VERSION ""

NS_ :

BS_:

BU_: VCU BMS ECUMASTER_GPS_IMU AMK_RL AMK_RR AMK_FL AML_FR BOSCH_IMU

BO_ 256 VCU_STATUS: 4 VCU
 SG_ VEHICLE_STATE : 0|2@1+ (1,0) [0|3] "Enum" Vector__XXX
 SG_ TORQUE_PLAUSIBLE : 2|1@1+ (1,0) [0|1] "Bool" Vector__XXX
 SG_ PEDALS_PLAUSIBLE : 3|1@1+ (1,0) [0|1] "Bool" Vector__XXX
 SG_ TORQUE_DERATING : 4|1@1+ (1,0) [0|1] "Bool" Vector__XXX
 SG_ VCU_EEPROM_STATE : 5|2@1+ (1,0) [0|1] "Enum" Vector__XXX
 SG_ CAN_PLAUSIBLE : 7|1@1+ (1,0) [0|1] "Bool" Vector__XXX
 SG_ APPS_1_PLAUSIBLE : 8|1@1+ (1,0) [0|1] "Bool" Vector__XXX
 SG_ APPS_1_CONFIG_PLAUSIBLE : 9|1@1+ (1,0) [0|1] "Bool" Vector__XXX
 SG_ APPS_2_PLAUSIBLE : 10|1@1+ (1,0) [0|1] "Bool" Vector__XXX
 SG_ APPS_2_CONFIG_PLAUSIBLE : 11|1@1+ (1,0) [0|1] "Bool" Vector__XXX
 SG_ BSE_F_PLAUSIBLE : 12|1@1+ (1,0) [0|1] "Bool" Vector__XXX
 SG_ BSE_F_CONFIG_PLAUSIBLE : 13|1@1+ (1,0) [0|1] "Bool" Vector__XXX
 SG_ BSE_R_PLAUSIBLE : 14|1@1+ (1,0) [0|1] "Bool" Vector__XXX
 SG_ BSE_R_CONFIG_PLAUSIBLE : 15|1@1+ (1,0) [0|1] "Bool" Vector__XXX
 SG_ AMK_RL_VALID : 16|1@1+ (1,0) [0|1] "Bool" Vector__XXX
 SG_ AMK_RR_VALID : 17|1@1+ (1,0) [0|1] "Bool" Vector__XXX
 SG_ AMK_FL_VALID : 18|1@1+ (1,0) [0|1] "Bool" Vector__XXX
 SG_ AMK_FR_VALID : 19|1@1+ (1,0) [0|1] "Bool" Vector__XXX
 SG_ ECUMASTER_STATUS : 20|2@1+ (1,0) [0|3] "Enum" Vector__XXX
 SG_ GLV_BATTERY_VOLTAGE : 24|8@1+ (0.070588235294,0) [0|18] "V" Vector__XXX
 SG_ SAS_STATE : 22|2@1+ (1,0) [0|3] "Enum" Vector__XXX

BO_ 1831 BMS_STATUS: 6 BMS
 SG_ BMS_UNDERVOLTAGE_FAULT : 0|1@1+ (1,0) [0|1] "Bool" Vector__XXX
 SG_ BMS_OVERVOLTAGE_FAULT : 1|1@1+ (1,0) [0|1] "Bool" Vector__XXX
 SG_ BMS_UNDERTEMPERATURE_FAULT : 2|1@1+ (1,0) [0|1] "Bool" Vector__XXX
 SG_ BMS_OVERTEMPERATURE_FAULT : 3|1@1+ (1,0) [0|1] "Bool" Vector__XXX
 SG_ BMS_SENSE_LINE_FAULT : 4|1@1+ (1,0) [0|1] "Bool" Vector__XXX
 SG_ BMS_ISOSPI_FAULT : 5|1@1+ (1,0) [0|1] "Bool" Vector__XXX
 SG_ BMS_SELF_TEST_FAULT : 6|1@1+ (1,0) [0|1] "Bool" Vector__XXX
 SG_ BMS_LTC_0_ISOSPI_FAULT : 16|1@1+ (1,0) [0|1] "Bool" Vector__XXX
 SG_ BMS_LTC_1_ISOSPI_FAULT : 17|1@1+ (1,0) [0|1] "Bool" Vector__XXX
 SG_ BMS_LTC_2_ISOSPI_FAULT : 18|1@1+ (1,0) [0|1] "Bool" Vector__XXX
 SG_ BMS_LTC_3_ISOSPI_FAULT : 19|1@1+ (1,0) [0|1] "Bool" Vector__XXX
 SG_ BMS_LTC_4_ISOSPI_FAULT : 20|1@1+ (1,0) [0|1] "Bool" Vector__XXX
 SG_ BMS_LTC_5_ISOSPI_FAULT : 21|1@1+ (1,0) [0|1] "Bool" Vector__XXX
 SG_ BMS_LTC_6_ISOSPI_FAULT : 22|1@1+ (1,0) [0|1] "Bool" Vector__XXX
 SG_ BMS_LTC_7_ISOSPI_FAULT : 23|1@1+ (1,0) [0|1] "Bool" Vector__XXX
 SG_ BMS_LTC_8_ISOSPI_FAULT : 24|1@1+ (1,0) [0|1] "Bool" Vector__XXX
 SG_ BMS_LTC_9_ISOSPI_FAULT : 25|1@1+ (1,0) [0|1] "Bool" Vector__XXX
 SG_ BMS_LTC_10_ISOSPI_FAULT : 26|1@1+ (1,0) [0|1] "Bool" Vector__XXX
 SG_ BMS_LTC_11_ISOSPI_FAULT : 27|1@1+ (1,0) [0|1] "Bool" Vector__XXX
 SG_ BMS_LTC_0_SELF_TEST_FAULT : 32|1@1+ (1,0) [0|1] "Bool" Vector__XXX
 SG_ BMS_LTC_1_SELF_TEST_FAULT : 33|1@1+ (1,0) [0|1] "Bool" Vector__XXX
 SG_ BMS_LTC_2_SELF_TEST_FAULT : 34|1@1+ (1,0) [0|1] "Bool" Vector__XXX
 SG_ BMS_LTC_3_SELF_TEST_FAULT : 35|1@1+ (1,0) [0|1] "Bool" Vector__XXX
 SG_ BMS_LTC_4_SELF_TEST_FAULT : 36|1@1+ (1,0) [0|1] "Bool" Vector__XXX
 SG_ BMS_LTC_5_SELF_TEST_FAULT : 37|1@1+ (1,0) [0|1] "Bool" Vector__XXX
 SG_ BMS_LTC_6_SELF_TEST_FAULT : 38|1@1+ (1,0) [0|1] "Bool" Vector__XXX
 SG_ BMS_LTC_7_SELF_TEST_FAULT : 39|1@1+ (1,0) [0|1] "Bool" Vector__XXX
 SG_ BMS_LTC_8_SELF_TEST_FAULT : 40|1@1+ (1,0) [0|1] "Bool" Vector__XXX
 SG_ BMS_LTC_9_SELF_TEST_FAULT : 41|1@1+ (1,0) [0|1] "Bool" Vector__XXX
 SG_ BMS_LTC_10_SELF_TEST_FAULT : 42|1@1+ (1,0) [0|1] "Bool" Vector__XXX
 SG_ BMS_LTC_11_SELF_TEST_FAULT : 43|1@1+ (1,0) [0|1] "Bool" Vector__XXX
 SG_ BMS_CHARGING : 7|1@1+ (1,0) [0|1] "Bool" Vector__XXX
 SG_ BMS_BALANCING : 8|1@1+ (1,0) [0|1] "Bool" Vector__XXX
 SG_ SHUTDOWN_CLOSED : 9|1@1+ (1,0) [0|1] "Bool" Vector__XXX
 SG_ PRECHARGE_COMPLETE : 10|1@1+ (1,0) [0|1] "Bool" Vector__XXX
 SG_ SHUTDOWN_LOOP_BLIP : 11|1@1+ (1,0) [0|1] "Bool" Vector__XXX
 SG_ BMS_RELAY_STATUS : 12|1@1+ (1,0) [0|1] "Bool" Vector__XXX
 SG_ IMD_RELAY_STATUS : 13|1@1+ (1,0) [0|1] "Bool" Vector__XXX

BO_ 1536 VCU_SENSOR_INPUT: 8 VCU
 SG_ APPS_1_PERCENT : 0|12@1+ (0.02442002442002442,0) [0|100] "%" Vector__XXX
 SG_ APPS_2_PERCENT : 12|12@1+ (0.02442002442002442,0) [0|100] "%" Vector__XXX
 SG_ BSE_FRONT_PERCENT : 24|12@1+ (0.02442002442002442,0) [0|100] "%" Vector__XXX
 SG_ BSE_REAR_PERCENT : 36|12@1+ (0.02442002442002442,0) [0|100] "%" Vector__XXX
 SG_ STEERING_ANGLE : 48|16@1- (0.005493247882810711,0) [-180|180] "Deg" Vector__XXX

BO_ 1832 BMS_POWER_CONSUMPTION: 4 BMS
 SG_ PACK_VOLTAGE : 0|16@1+ (0.0125,0) [0|819.2] "V" Vector__XXX
 SG_ PACK_CURRENT : 16|16@1- (0.019073486328125,0) [-625|625] "A" Vector__XXX

BO_ 512 AMK_RL_MOTOR_REQUEST: 8 VCU
 SG_ RL_INVERTER_ENABLE : 8|1@1+ (1,0) [0|1] "" Vector__XXX
 SG_ RL_DC_ENABLE : 9|1@1+ (1,0) [0|1] "" Vector__XXX
 SG_ RL_DRIVER_ENABLE : 10|1@1+ (1,0) [0|1] "" Vector__XXX
 SG_ RL_ERROR_RESET : 11|1@1+ (1,0) [0|1] "" Vector__XXX
 SG_ RL_TORQUE_SETPOINT : 16|16@1- (0.0098,0) [-21|21] "Nm" Vector__XXX
 SG_ RL_POSITIVE_TORQUE_LIMIT : 32|16@1- (0.0098,0) [0|21] "Nm" Vector__XXX
 SG_ RL_NEGATIVE_TORQUE_LIMIT : 48|16@1- (0.0098,0) [0|21] "Nm" Vector__XXX

BO_ 513 AMK_RR_MOTOR_REQUEST: 8 VCU
 SG_ RR_INVERTER_ENABLE : 8|1@1+ (1,0) [0|1] "" Vector__XXX
 SG_ RR_DC_ENABLE : 9|1@1+ (1,0) [0|1] "" Vector__XXX
 SG_ RR_DRIVER_ENABLE : 10|1@1+ (1,0) [0|1] "" Vector__XXX
 SG_ RR_ERROR_RESET : 11|1@1+ (1,0) [0|1] "" Vector__XXX
 SG_ RR_TORQUE_SETPOINT : 16|16@1- (0.0098,0) [-21|21] "Nm" Vector__XXX
 SG_ RR_POSITIVE_TORQUE_LIMIT : 32|16@1- (0.0098,0) [0|21] "Nm" Vector__XXX
 SG_ RR_NEGATIVE_TORQUE_LIMIT : 48|16@1- (0.0098,0) [0|21] "Nm" Vector__XXX

BO_ 514 AMK_FL_MOTOR_REQUEST: 8 VCU
 SG_ FL_INVERTER_ENABLE : 8|1@1+ (1,0) [0|1] "" Vector__XXX
 SG_ FL_DC_ENABLE : 9|1@1+ (1,0) [0|1] "" Vector__XXX
 SG_ FL_DRIVER_ENABLE : 10|1@1+ (1,0) [0|1] "" Vector__XXX
 SG_ FL_ERROR_RESET : 11|1@1+ (1,0) [0|1] "" Vector__XXX
 SG_ FL_TORQUE_SETPOINT : 16|16@1- (0.0098,0) [-21|21] "Nm" Vector__XXX
 SG_ FL_POSITIVE_TORQUE_LIMIT : 32|16@1- (0.0098,0) [0|21] "Nm" Vector__XXX
 SG_ FL_NEGATIVE_TORQUE_LIMIT : 48|16@1- (0.0098,0) [0|21] "Nm" Vector__XXX

BO_ 515 AMK_FR_MOTOR_REQUEST: 8 VCU
 SG_ FR_INVERTER_ENABLE : 8|1@1+ (1,0) [0|1] "" Vector__XXX
 SG_ FR_DC_ENABLE : 9|1@1+ (1,0) [0|1] "" Vector__XXX
 SG_ FR_DRIVER_ENABLE : 10|1@1+ (1,0) [0|1] "" Vector__XXX
 SG_ FR_ERROR_RESET : 11|1@1+ (1,0) [0|1] "" Vector__XXX
 SG_ FR_TORQUE_SETPOINT : 16|16@1- (0.0098,0) [-21|21] "Nm" Vector__XXX
 SG_ FR_POSITIVE_TORQUE_LIMIT : 32|16@1- (0.0098,0) [0|21] "Nm" Vector__XXX
 SG_ FR_NEGATIVE_TORQUE_LIMIT : 48|16@1- (0.0098,0) [0|21] "Nm" Vector__XXX

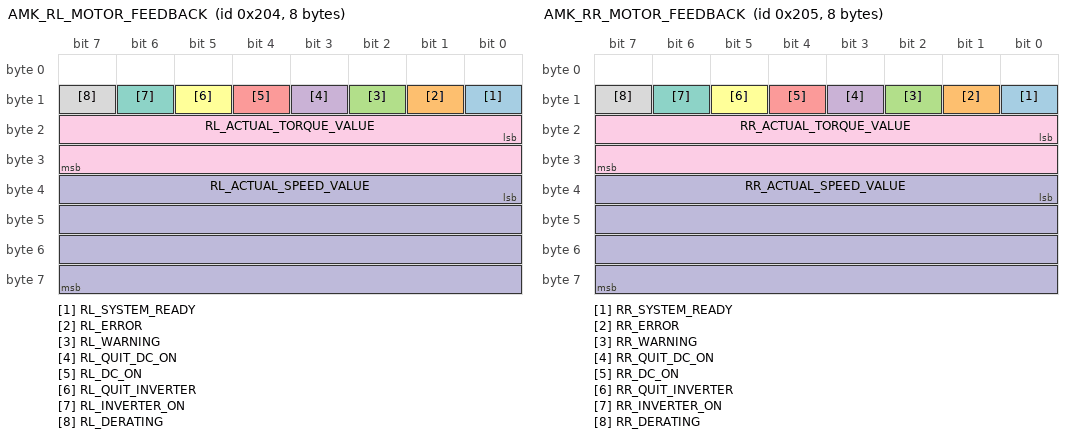
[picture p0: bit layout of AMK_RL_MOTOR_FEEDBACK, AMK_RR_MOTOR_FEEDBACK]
BO_ 516 AMK_RL_MOTOR_FEEDBACK: 8 AMK_RL
 SG_ RL_SYSTEM_READY : 8|1@1+ (1,0) [0|1] "Bool" Vector__XXX
 SG_ RL_ERROR : 9|1@1+ (1,0) [0|1] "Bool" Vector__XXX
 SG_ RL_WARNING : 10|1@1+ (1,0) [0|1] "Bool" Vector__XXX
 SG_ RL_QUIT_DC_ON : 11|1@1+ (1,0) [0|1] "Bool" Vector__XXX
 SG_ RL_DC_ON : 12|1@1+ (1,0) [0|1] "Bool" Vector__XXX
 SG_ RL_QUIT_INVERTER : 13|1@1+ (1,0) [0|1] "Bool" Vector__XXX
 SG_ RL_INVERTER_ON : 14|1@1+ (1,0) [0|1] "Bool" Vector__XXX
 SG_ RL_DERATING : 15|1@1+ (1,0) [0|1] "Bool" Vector__XXX
 SG_ RL_ACTUAL_TORQUE_VALUE : 16|16@1- (0.0098,0) [0|0] "Nm" Vector__XXX
 SG_ RL_ACTUAL_SPEED_VALUE : 32|32@1- (0.0001,0) [0|0] "RPM" Vector__XXX

BO_ 517 AMK_RR_MOTOR_FEEDBACK: 8 AMK_RR
 SG_ RR_SYSTEM_READY : 8|1@1+ (1,0) [0|1] "Bool" Vector__XXX
 SG_ RR_ERROR : 9|1@1+ (1,0) [0|1] "Bool" Vector__XXX
 SG_ RR_WARNING : 10|1@1+ (1,0) [0|1] "Bool" Vector__XXX
 SG_ RR_QUIT_DC_ON : 11|1@1+ (1,0) [0|1] "Bool" Vector__XXX
 SG_ RR_DC_ON : 12|1@1+ (1,0) [0|1] "Bool" Vector__XXX
 SG_ RR_QUIT_INVERTER : 13|1@1+ (1,0) [0|1] "Bool" Vector__XXX
 SG_ RR_INVERTER_ON : 14|1@1+ (1,0) [0|1] "Bool" Vector__XXX
 SG_ RR_DERATING : 15|1@1+ (1,0) [0|1] "Bool" Vector__XXX
 SG_ RR_ACTUAL_TORQUE_VALUE : 16|16@1- (0.0098,0) [0|0] "Nm" Vector__XXX
 SG_ RR_ACTUAL_SPEED_VALUE : 32|32@1- (0.0001,0) [0|0] "RPM" Vector__XXX

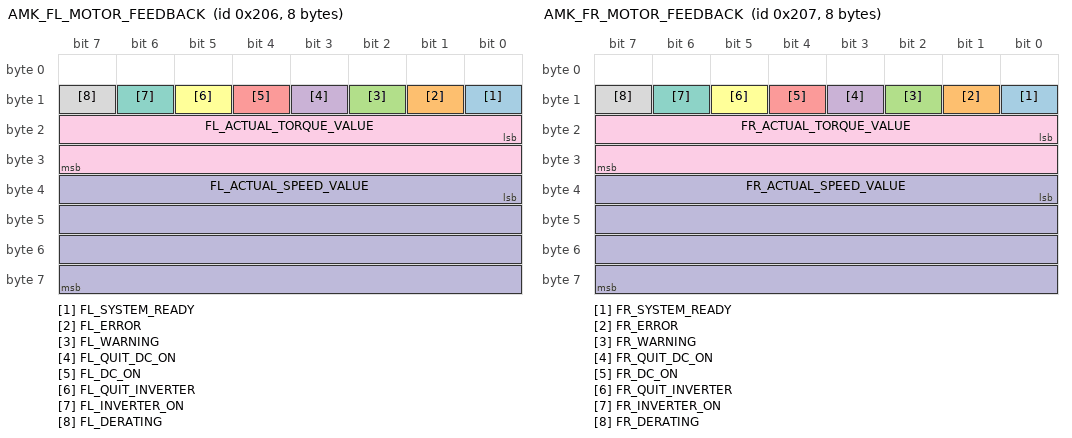
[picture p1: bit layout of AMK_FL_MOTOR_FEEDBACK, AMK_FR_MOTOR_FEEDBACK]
BO_ 518 AMK_FL_MOTOR_FEEDBACK: 8 AMK_FL
 SG_ FL_SYSTEM_READY : 8|1@1+ (1,0) [0|1] "Bool" Vector__XXX
 SG_ FL_ERROR : 9|1@1+ (1,0) [0|1] "Bool" Vector__XXX
 SG_ FL_WARNING : 10|1@1+ (1,0) [0|1] "Bool" Vector__XXX
 SG_ FL_QUIT_DC_ON : 11|1@1+ (1,0) [0|1] "Bool" Vector__XXX
 SG_ FL_DC_ON : 12|1@1+ (1,0) [0|1] "Bool" Vector__XXX
 SG_ FL_QUIT_INVERTER : 13|1@1+ (1,0) [0|1] "Bool" Vector__XXX
 SG_ FL_INVERTER_ON : 14|1@1+ (1,0) [0|1] "Bool" Vector__XXX
 SG_ FL_DERATING : 15|1@1+ (1,0) [0|1] "Bool" Vector__XXX
 SG_ FL_ACTUAL_TORQUE_VALUE : 16|16@1- (0.0098,0) [0|0] "Nm" Vector__XXX
 SG_ FL_ACTUAL_SPEED_VALUE : 32|32@1- (0.0001,0) [0|0] "RPM" Vector__XXX

BO_ 519 AMK_FR_MOTOR_FEEDBACK: 8 AMK_FR
 SG_ FR_SYSTEM_READY : 8|1@1+ (1,0) [0|1] "Bool" Vector__XXX
 SG_ FR_ERROR : 9|1@1+ (1,0) [0|1] "Bool" Vector__XXX
 SG_ FR_WARNING : 10|1@1+ (1,0) [0|1] "Bool" Vector__XXX
 SG_ FR_QUIT_DC_ON : 11|1@1+ (1,0) [0|1] "Bool" Vector__XXX
 SG_ FR_DC_ON : 12|1@1+ (1,0) [0|1] "Bool" Vector__XXX
 SG_ FR_QUIT_INVERTER : 13|1@1+ (1,0) [0|1] "Bool" Vector__XXX
 SG_ FR_INVERTER_ON : 14|1@1+ (1,0) [0|1] "Bool" Vector__XXX
 SG_ FR_DERATING : 15|1@1+ (1,0) [0|1] "Bool" Vector__XXX
 SG_ FR_ACTUAL_TORQUE_VALUE : 16|16@1- (0.0098,0) [0|0] "Nm" Vector__XXX
 SG_ FR_ACTUAL_SPEED_VALUE : 32|32@1- (0.0001,0) [0|0] "RPM" Vector__XXX

BO_ 1284 AMK_RL_ERRORS_1: 8 AMK_RL
 SG_ RL_DIAGNOSTIC_NUMBER : 0|32@1+ (1,0) [0|4294967295] "Word" Vector__XXX
 SG_ RL_ERROR_INFO_1 : 32|32@1+ (1,0) [0|4294967295] "Word" Vector__XXX

BO_ 1285 AMK_RR_ERRORS_1: 8 AMK_RR
 SG_ RR_DIAGNOSTIC_NUMBER : 0|32@1+ (1,0) [0|4294967295] "Word" Vector__XXX
 SG_ RR_ERROR_INFO_1 : 32|32@1+ (1,0) [0|4294967295] "Word" Vector__XXX

BO_ 1286 AMK_FL_ERRORS_1: 8 AMK_FL
 SG_ FL_DIAGNOSTIC_NUMBER : 0|32@1+ (1,0) [0|4294967295] "Word" Vector__XXX
 SG_ FL_ERROR_INFO_1 : 32|32@1+ (1,0) [0|4294967295] "Word" Vector__XXX

BO_ 1287 AMK_FR_ERRORS_1: 8 AMK_FR
 SG_ FR_DIAGNOSTIC_NUMBER : 0|32@1+ (1,0) [0|4294967295] "Word" Vector__XXX
 SG_ FR_ERROR_INFO_1 : 32|32@1+ (1,0) [0|4294967295] "Word" Vector__XXX

BO_ 1288 AMK_RL_ERRORS_2: 8 AMK_RL
 SG_ RL_ERROR_INFO_2 : 0|32@1+ (1,0) [0|4294967295] "Word" Vector__XXX
 SG_ RL_ERROR_INFO_3 : 32|32@1+ (1,0) [0|4294967295] "Word" Vector__XXX

BO_ 1289 AMK_RR_ERRORS_2: 8 AMK_RR
 SG_ RR_ERROR_INFO_2 : 0|32@1+ (1,0) [0|4294967295] "Word" Vector__XXX
 SG_ RR_ERROR_INFO_3 : 32|32@1+ (1,0) [0|4294967295] "Word" Vector__XXX

BO_ 1290 AMK_FL_ERRORS_2: 8 AMK_FL
 SG_ FL_ERROR_INFO_2 : 0|32@1+ (1,0) [0|4294967295] "Word" Vector__XXX
 SG_ FL_ERROR_INFO_3 : 32|32@1+ (1,0) [0|4294967295] "Word" Vector__XXX

BO_ 1291 AMK_FR_ERRORS_2: 8 AMK_FR
 SG_ FR_ERROR_INFO_2 : 0|32@1+ (1,0) [0|4294967295] "Word" Vector__XXX
 SG_ FR_ERROR_INFO_3 : 32|32@1+ (1,0) [0|4294967295] "Word" Vector__XXX

BO_ 520 AMK_RL_POWER_CONSUMPTION: 8 AMK_RL
 SG_ RL_DC_BUS_VOLTAGE : 0|16@1+ (1,0) [0|0] "V" Vector__XXX
 SG_ RL_TORQUE_CURRENT_FEEDBACK : 16|16@1- (1,0) [0|0] "A" Vector__XXX
 SG_ RL_ACTUAL_POWER_VALUE : 32|32@1+ (1,0) [0|0] "W" Vector__XXX

BO_ 521 AMK_RR_POWER_CONSUMPTION: 8 AMK_RR
 SG_ RR_DC_BUS_VOLTAGE : 0|16@1+ (1,0) [0|0] "V" Vector__XXX
 SG_ RR_TORQUE_CURRENT_FEEDBACK : 16|16@1- (1,0) [0|0] "A" Vector__XXX
 SG_ RR_ACTUAL_POWER_VALUE : 32|32@1+ (1,0) [0|0] "W" Vector__XXX

BO_ 522 AMK_FL_POWER_CONSUMPTION: 8 AMK_FL
 SG_ FL_DC_BUS_VOLTAGE : 0|16@1+ (1,0) [0|0] "V" Vector__XXX
 SG_ FL_TORQUE_CURRENT_FEEDBACK : 16|16@1- (1,0) [0|0] "A" Vector__XXX
 SG_ FL_ACTUAL_POWER_VALUE : 32|32@1+ (1,0) [0|0] "W" Vector__XXX

BO_ 523 AMK_FR_POWER_CONSUMPTION: 8 AMK_FR
 SG_ FR_DC_BUS_VOLTAGE : 0|16@1+ (1,0) [0|0] "V" Vector__XXX
 SG_ FR_TORQUE_CURRENT_FEEDBACK : 16|16@1- (1,0) [0|0] "A" Vector__XXX
 SG_ FR_ACTUAL_POWER_VALUE : 32|32@1+ (1,0) [0|0] "W" Vector__XXX

BO_ 1280 AMK_RL_TEMPERATURES: 8 AMK_RL
 SG_ RL_TEMPERATURE_INTERNAL : 0|16@1- (0.1,0) [0|0] "C" Vector__XXX
 SG_ RL_TEMPERATURE_EXTERNAL : 16|16@1- (0.1,0) [0|0] "C" Vector__XXX
 SG_ RL_TEMPERATURE_SENSOR_MOTOR : 32|16@1+ (0.1,0) [0|0] "C" Vector__XXX
 SG_ RL_IGBT_TEMPERATURE : 48|16@1- (0.1,0) [0|0] "C" Vector__XXX

BO_ 1281 AMK_RR_TEMPERATURES: 8 AMK_RR
 SG_ RR_TEMPERATURE_INTERNAL : 0|16@1- (0.1,0) [0|0] "C" Vector__XXX
 SG_ RR_TEMPERATURE_EXTERNAL : 16|16@1- (0.1,0) [0|0] "C" Vector__XXX
 SG_ RR_TEMPERATURE_SENSOR_MOTOR : 32|16@1+ (0.1,0) [0|0] "C" Vector__XXX
 SG_ RR_IGBT_TEMPERATURE : 48|16@1- (0.1,0) [0|0] "C" Vector__XXX

BO_ 1282 AMK_FL_TEMPERATURES: 8 AMK_FL
 SG_ FL_TEMPERATURE_INTERNAL : 0|16@1- (0.1,0) [0|0] "C" Vector__XXX
 SG_ FL_TEMPERATURE_EXTERNAL : 16|16@1- (0.1,0) [0|0] "C" Vector__XXX
 SG_ FL_TEMPERATURE_SENSOR_MOTOR : 32|16@1+ (0.1,0) [0|0] "C" Vector__XXX
 SG_ FL_IGBT_TEMPERATURE : 48|16@1- (0.1,0) [0|0] "C" Vector__XXX

BO_ 1283 AMK_FR_TEMPERATURES: 8 AMK_FR
 SG_ FR_TEMPERATURE_INTERNAL : 0|16@1- (0.1,0) [0|0] "C" Vector__XXX
 SG_ FR_TEMPERATURE_EXTERNAL : 16|16@1- (0.1,0) [0|0] "C" Vector__XXX
 SG_ FR_TEMPERATURE_SENSOR_MOTOR : 32|16@1+ (0.1,0) [0|0] "C" Vector__XXX
 SG_ FR_IGBT_TEMPERATURE : 48|16@1- (0.1,0) [0|0] "C" Vector__XXX

BO_ 1024 ECUMASTER_GPS_POSITION: 8 ECUMASTER_GPS_IMU
 SG_ LATITUDE : 7|32@0- (1e-7,0) [-90|90] "deg" Vector__XXX
 SG_ LONGITUDE : 39|32@0- (1e-7,0) [-180|180] "deg" Vector__XXX

BO_ 1025 ECUMASTER_GPS_VELOCITY: 8 ECUMASTER_GPS_IMU
 SG_ SPEED : 7|16@0- (0.036,0) [-1179|1179] "km/h" Vector__XXX
 SG_ HEIGHT : 23|16@0- (1,0) [-32768|32767] "m" Vector__XXX
 SG_ SATELLITES_NUMBER : 47|8@0+ (1,0) [0|72] "" Vector__XXX
 SG_ GPS_FRAME_INDEX : 51|4@0+ (1,0) [0|16] "" Vector__XXX
 SG_ EMPTY_FRAME_INDEX : 55|4@0+ (1,0) [0|16] "" Vector__XXX
 SG_ GPS_STATUS : 58|3@0+ (1,0) [1|5] "" Vector__XXX

BO_ 1026 ECUMASTER_GPS_HEADING_IMU0: 8 ECUMASTER_GPS_IMU
 SG_ HEADING_MOTION : 7|16@0+ (1,0) [0|360] "deg" Vector__XXX
 SG_ HEADING_VEHICLE : 23|16@0+ (1,0) [0|360] "deg" Vector__XXX
 SG_ ECUMASTER_X_ANGLE_RATE : 39|16@0- (0.01,0) [-250|250] "deg/s" Vector__XXX
 SG_ ECUMASTER_Y_ANGLE_RATE : 55|16@0- (0.01,0) [-250|250] "deg/s" Vector__XXX

BO_ 1027 ECUMASTER_GPS_IMU1: 8 ECUMASTER_GPS_IMU
 SG_ ECUMASTER_Z_ANGLE_RATE : 7|16@0- (0.01,0) [-250|250] "deg/s" Vector__XXX
 SG_ ECUMASTER_X_ACCELERATION : 23|16@0- (0.01,0) [-4|4] "g" Vector__XXX
 SG_ ECUMASTER_Y_ACCELERATION : 39|16@0- (0.01,0) [-4|4] "g" Vector__XXX
 SG_ ECUMASTER_Z_ACCELERATION : 55|16@0- (0.01,0) [-4|4] "g" Vector__XXX

BO_ 1028 ECUMASTER_GPS_UTC: 8 ECUMASTER_GPS_IMU
 SG_ UTC_YEAR : 7|8@0+ (1,2000) [2000|2255] "years" Vector__XXX
 SG_ UTC_MONTH : 15|8@0+ (1,0) [1|12] "months" Vector__XXX
 SG_ UTC_DAY : 23|8@0+ (1,0) [1|31] "days" Vector__XXX
 SG_ UTC_HOUR : 31|8@0+ (1,0) [0|23] "hours" Vector__XXX
 SG_ UTC_MINUTE : 39|8@0+ (1,0) [0|59] "minutes" Vector__XXX
 SG_ UTC_SECOND : 47|8@0+ (1,0) [0|59] "s" Vector__XXX
 SG_ UTC_MILLISECOND : 55|16@0+ (0.0152587890625,0) [0|999.99] "ms" Vector__XXX

BO_ 372 BOSCH_IMU_1: 8 BOSCH_IMU
 SG_ BOSCH_Z_ANGLE_RATE : 0|16@1+ (0.005,-163.84) [-163.84|163.84] "deg/s" Vector__XXX
 SG_ BOSCH_Y_ACCELERATION : 32|16@1+ (0.0001274,-4.1746432) [-4.1746432|4.1746432] "g" Vector__XXX

BO_ 376 BOSCH_IMU_2: 8 BOSCH_IMU
 SG_ BOSCH_X_ANGLE_RATE : 0|16@1+ (0.005,-163.84) [-163.84|163.84] "deg/s" Vector__XXX
 SG_ BOSCH_X_ACCELERATION : 32|16@1+ (0.0001274,-4.1746432) [-4.1746432|4.1746432] "g" Vector__XXX

BO_ 380 BOSCH_IMU_3: 8 BOSCH_IMU
 SG_ BOSCH_Z_ACCELERATION : 32|16@1+ (0.0001274,-4.1746432) [-4.1746432|4.1746432] "g" Vector__XXX

BO_ 384 DATA_LOGGER_STATUS: 4 Vector__XXX
 SG_ MIN_BUS_LOAD : 0|8@1+ (0.6,0) [0|153] "%" Vector__XXX
 SG_ MAX_BUS_LOAD : 8|8@1+ (0.6,0) [0|153] "%" Vector__XXX
 SG_ ERROR_FRAME_COUNT : 16|16@1+ (1,0) [0|65535] "" Vector__XXX

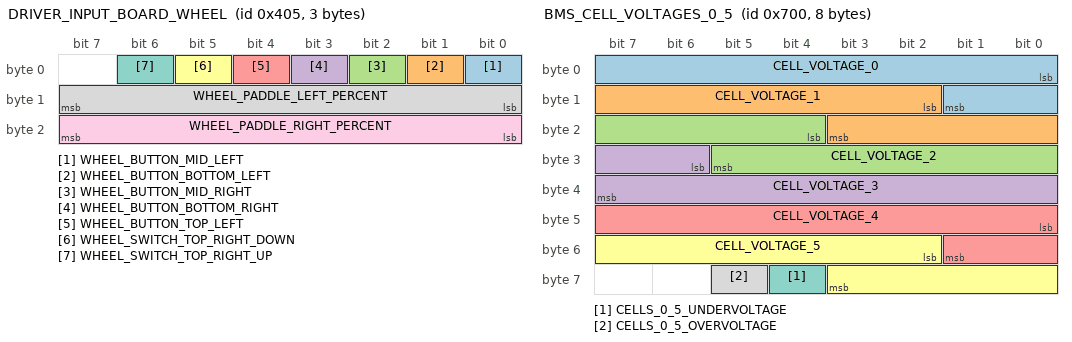
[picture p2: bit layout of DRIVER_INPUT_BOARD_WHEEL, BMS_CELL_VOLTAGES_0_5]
BO_ 1029 DRIVER_INPUT_BOARD_WHEEL: 3 Vector__XXX
 SG_ WHEEL_BUTTON_MID_LEFT : 0|1@1+ (1,0) [0|1] "Bool" Vector__XXX
 SG_ WHEEL_BUTTON_BOTTOM_LEFT : 1|1@1+ (1,0) [0|1] "Bool" Vector__XXX
 SG_ WHEEL_BUTTON_MID_RIGHT : 2|1@1+ (1,0) [0|1] "Bool" Vector__XXX
 SG_ WHEEL_BUTTON_BOTTOM_RIGHT : 3|1@1+ (1,0) [0|1] "Bool" Vector__XXX
 SG_ WHEEL_BUTTON_TOP_LEFT : 4|1@1+ (1,0) [0|1] "Bool" Vector__XXX
 SG_ WHEEL_SWITCH_TOP_RIGHT_DOWN : 5|1@1+ (1,0) [0|1] "Bool" Vector__XXX
 SG_ WHEEL_SWITCH_TOP_RIGHT_UP : 6|1@1+ (1,0) [0|1] "Bool" Vector__XXX
 SG_ WHEEL_PADDLE_LEFT_PERCENT : 8|8@1+ (0.392156862745,0) [0|100] "%" Vector__XXX
 SG_ WHEEL_PADDLE_RIGHT_PERCENT : 16|8@1+ (0.392156862745,0) [0|100] "%" Vector__XXX

BO_ 1952 VEHICLE_CONFIG: 4 VCU
 SG_ DRIVING_TORQUE_LIMIT : 0|8@1+ (0.39215686274509803,0) [0|100] "Nm" Vector__XXX
 SG_ DRIVING_TORQUE_F_R_BIAS : 8|8@1+ (0.00392156862745098,0) [0|1] "Ratio" Vector__XXX
 SG_ DRIVING_TORQUE_L_R_BIAS : 16|8@1+ (0.00392156862745098,0) [0|1] "Ratio" Vector__XXX
 SG_ TORQUE_ALGORITHM_INDEX : 24|8@1+ (1,0) [0|255] "Index" Vector__XXX

BO_ 1956 DRS_STATUS: 2 Vector__XXX
 SG_ THETA_TARGET : 0|10@1+ (0.3515625,-180) [-180|180] "" Vector__XXX
 SG_ WING_STATUS : 10|3@1+ (1,0) [0|7] "" Vector__XXX
 SG_ EEPROM_STATUS : 13|2@1+ (1,0) [0|3] "" Vector__XXX
 SG_ STALLED : 15|1@1+ (1,0) [0|1] "" Vector__XXX

BO_ 1792 BMS_CELL_VOLTAGES_0_5: 8 BMS
 SG_ CELL_VOLTAGE_0 : 0|10@1+ (0.0078125,0) [0|8] "V" Vector__XXX
 SG_ CELL_VOLTAGE_1 : 10|10@1+ (0.0078125,0) [0|8] "V" Vector__XXX
 SG_ CELL_VOLTAGE_2 : 20|10@1+ (0.0078125,0) [0|8] "V" Vector__XXX
 SG_ CELL_VOLTAGE_3 : 30|10@1+ (0.0078125,0) [0|8] "V" Vector__XXX
 SG_ CELL_VOLTAGE_4 : 40|10@1+ (0.0078125,0) [0|8] "V" Vector__XXX
 SG_ CELL_VOLTAGE_5 : 50|10@1+ (0.0078125,0) [0|8] "V" Vector__XXX
 SG_ CELLS_0_5_UNDERVOLTAGE : 60|1@1+ (1,0) [0|1] "Bool" Vector__XXX
 SG_ CELLS_0_5_OVERVOLTAGE : 61|1@1+ (1,0) [0|1] "Bool" Vector__XXX

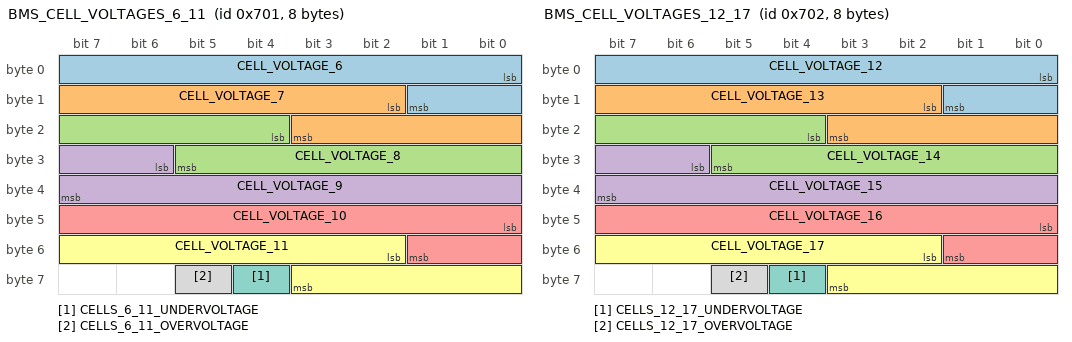
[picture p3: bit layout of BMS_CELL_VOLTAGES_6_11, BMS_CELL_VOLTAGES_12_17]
BO_ 1793 BMS_CELL_VOLTAGES_6_11: 8 BMS
 SG_ CELL_VOLTAGE_6 : 0|10@1+ (0.0078125,0) [0|8] "V" Vector__XXX
 SG_ CELL_VOLTAGE_7 : 10|10@1+ (0.0078125,0) [0|8] "V" Vector__XXX
 SG_ CELL_VOLTAGE_8 : 20|10@1+ (0.0078125,0) [0|8] "V" Vector__XXX
 SG_ CELL_VOLTAGE_9 : 30|10@1+ (0.0078125,0) [0|8] "V" Vector__XXX
 SG_ CELL_VOLTAGE_10 : 40|10@1+ (0.0078125,0) [0|8] "V" Vector__XXX
 SG_ CELL_VOLTAGE_11 : 50|10@1+ (0.0078125,0) [0|8] "V" Vector__XXX
 SG_ CELLS_6_11_UNDERVOLTAGE : 60|1@1+ (1,0) [0|1] "Bool" Vector__XXX
 SG_ CELLS_6_11_OVERVOLTAGE : 61|1@1+ (1,0) [0|1] "Bool" Vector__XXX

BO_ 1794 BMS_CELL_VOLTAGES_12_17: 8 BMS
 SG_ CELL_VOLTAGE_12 : 0|10@1+ (0.0078125,0) [0|8] "V" Vector__XXX
 SG_ CELL_VOLTAGE_13 : 10|10@1+ (0.0078125,0) [0|8] "V" Vector__XXX
 SG_ CELL_VOLTAGE_14 : 20|10@1+ (0.0078125,0) [0|8] "V" Vector__XXX
 SG_ CELL_VOLTAGE_15 : 30|10@1+ (0.0078125,0) [0|8] "V" Vector__XXX
 SG_ CELL_VOLTAGE_16 : 40|10@1+ (0.0078125,0) [0|8] "V" Vector__XXX
 SG_ CELL_VOLTAGE_17 : 50|10@1+ (0.0078125,0) [0|8] "V" Vector__XXX
 SG_ CELLS_12_17_UNDERVOLTAGE : 60|1@1+ (1,0) [0|1] "Bool" Vector__XXX
 SG_ CELLS_12_17_OVERVOLTAGE : 61|1@1+ (1,0) [0|1] "Bool" Vector__XXX

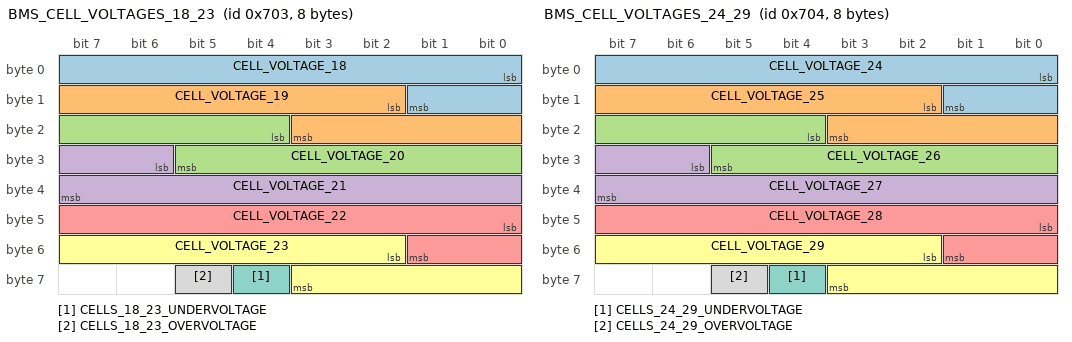
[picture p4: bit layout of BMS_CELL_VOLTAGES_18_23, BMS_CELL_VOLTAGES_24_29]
BO_ 1795 BMS_CELL_VOLTAGES_18_23: 8 BMS
 SG_ CELL_VOLTAGE_18 : 0|10@1+ (0.0078125,0) [0|8] "V" Vector__XXX
 SG_ CELL_VOLTAGE_19 : 10|10@1+ (0.0078125,0) [0|8] "V" Vector__XXX
 SG_ CELL_VOLTAGE_20 : 20|10@1+ (0.0078125,0) [0|8] "V" Vector__XXX
 SG_ CELL_VOLTAGE_21 : 30|10@1+ (0.0078125,0) [0|8] "V" Vector__XXX
 SG_ CELL_VOLTAGE_22 : 40|10@1+ (0.0078125,0) [0|8] "V" Vector__XXX
 SG_ CELL_VOLTAGE_23 : 50|10@1+ (0.0078125,0) [0|8] "V" Vector__XXX
 SG_ CELLS_18_23_UNDERVOLTAGE : 60|1@1+ (1,0) [0|1] "Bool" Vector__XXX
 SG_ CELLS_18_23_OVERVOLTAGE : 61|1@1+ (1,0) [0|1] "Bool" Vector__XXX

BO_ 1796 BMS_CELL_VOLTAGES_24_29: 8 BMS
 SG_ CELL_VOLTAGE_24 : 0|10@1+ (0.0078125,0) [0|8] "V" Vector__XXX
 SG_ CELL_VOLTAGE_25 : 10|10@1+ (0.0078125,0) [0|8] "V" Vector__XXX
 SG_ CELL_VOLTAGE_26 : 20|10@1+ (0.0078125,0) [0|8] "V" Vector__XXX
 SG_ CELL_VOLTAGE_27 : 30|10@1+ (0.0078125,0) [0|8] "V" Vector__XXX
 SG_ CELL_VOLTAGE_28 : 40|10@1+ (0.0078125,0) [0|8] "V" Vector__XXX
 SG_ CELL_VOLTAGE_29 : 50|10@1+ (0.0078125,0) [0|8] "V" Vector__XXX
 SG_ CELLS_24_29_UNDERVOLTAGE : 60|1@1+ (1,0) [0|1] "Bool" Vector__XXX
 SG_ CELLS_24_29_OVERVOLTAGE : 61|1@1+ (1,0) [0|1] "Bool" Vector__XXX

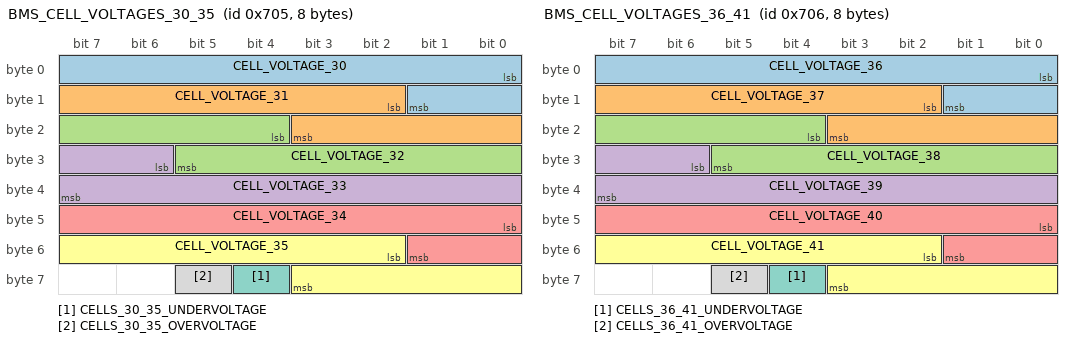
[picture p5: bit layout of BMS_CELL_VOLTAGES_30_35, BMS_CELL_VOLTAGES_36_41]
BO_ 1797 BMS_CELL_VOLTAGES_30_35: 8 BMS
 SG_ CELL_VOLTAGE_30 : 0|10@1+ (0.0078125,0) [0|8] "V" Vector__XXX
 SG_ CELL_VOLTAGE_31 : 10|10@1+ (0.0078125,0) [0|8] "V" Vector__XXX
 SG_ CELL_VOLTAGE_32 : 20|10@1+ (0.0078125,0) [0|8] "V" Vector__XXX
 SG_ CELL_VOLTAGE_33 : 30|10@1+ (0.0078125,0) [0|8] "V" Vector__XXX
 SG_ CELL_VOLTAGE_34 : 40|10@1+ (0.0078125,0) [0|8] "V" Vector__XXX
 SG_ CELL_VOLTAGE_35 : 50|10@1+ (0.0078125,0) [0|8] "V" Vector__XXX
 SG_ CELLS_30_35_UNDERVOLTAGE : 60|1@1+ (1,0) [0|1] "Bool" Vector__XXX
 SG_ CELLS_30_35_OVERVOLTAGE : 61|1@1+ (1,0) [0|1] "Bool" Vector__XXX

BO_ 1798 BMS_CELL_VOLTAGES_36_41: 8 BMS
 SG_ CELL_VOLTAGE_36 : 0|10@1+ (0.0078125,0) [0|8] "V" Vector__XXX
 SG_ CELL_VOLTAGE_37 : 10|10@1+ (0.0078125,0) [0|8] "V" Vector__XXX
 SG_ CELL_VOLTAGE_38 : 20|10@1+ (0.0078125,0) [0|8] "V" Vector__XXX
 SG_ CELL_VOLTAGE_39 : 30|10@1+ (0.0078125,0) [0|8] "V" Vector__XXX
 SG_ CELL_VOLTAGE_40 : 40|10@1+ (0.0078125,0) [0|8] "V" Vector__XXX
 SG_ CELL_VOLTAGE_41 : 50|10@1+ (0.0078125,0) [0|8] "V" Vector__XXX
 SG_ CELLS_36_41_UNDERVOLTAGE : 60|1@1+ (1,0) [0|1] "Bool" Vector__XXX
 SG_ CELLS_36_41_OVERVOLTAGE : 61|1@1+ (1,0) [0|1] "Bool" Vector__XXX

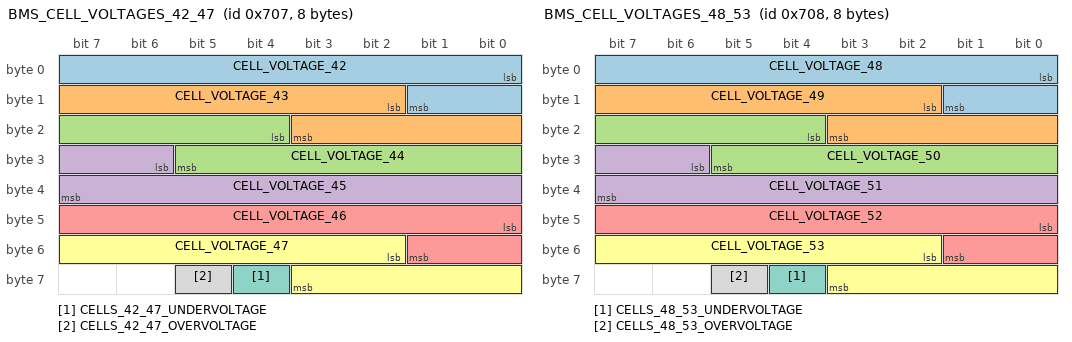
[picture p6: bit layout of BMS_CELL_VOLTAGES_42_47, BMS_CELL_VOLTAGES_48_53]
BO_ 1799 BMS_CELL_VOLTAGES_42_47: 8 BMS
 SG_ CELL_VOLTAGE_42 : 0|10@1+ (0.0078125,0) [0|8] "V" Vector__XXX
 SG_ CELL_VOLTAGE_43 : 10|10@1+ (0.0078125,0) [0|8] "V" Vector__XXX
 SG_ CELL_VOLTAGE_44 : 20|10@1+ (0.0078125,0) [0|8] "V" Vector__XXX
 SG_ CELL_VOLTAGE_45 : 30|10@1+ (0.0078125,0) [0|8] "V" Vector__XXX
 SG_ CELL_VOLTAGE_46 : 40|10@1+ (0.0078125,0) [0|8] "V" Vector__XXX
 SG_ CELL_VOLTAGE_47 : 50|10@1+ (0.0078125,0) [0|8] "V" Vector__XXX
 SG_ CELLS_42_47_UNDERVOLTAGE : 60|1@1+ (1,0) [0|1] "Bool" Vector__XXX
 SG_ CELLS_42_47_OVERVOLTAGE : 61|1@1+ (1,0) [0|1] "Bool" Vector__XXX

BO_ 1800 BMS_CELL_VOLTAGES_48_53: 8 BMS
 SG_ CELL_VOLTAGE_48 : 0|10@1+ (0.0078125,0) [0|8] "V" Vector__XXX
 SG_ CELL_VOLTAGE_49 : 10|10@1+ (0.0078125,0) [0|8] "V" Vector__XXX
 SG_ CELL_VOLTAGE_50 : 20|10@1+ (0.0078125,0) [0|8] "V" Vector__XXX
 SG_ CELL_VOLTAGE_51 : 30|10@1+ (0.0078125,0) [0|8] "V" Vector__XXX
 SG_ CELL_VOLTAGE_52 : 40|10@1+ (0.0078125,0) [0|8] "V" Vector__XXX
 SG_ CELL_VOLTAGE_53 : 50|10@1+ (0.0078125,0) [0|8] "V" Vector__XXX
 SG_ CELLS_48_53_UNDERVOLTAGE : 60|1@1+ (1,0) [0|1] "Bool" Vector__XXX
 SG_ CELLS_48_53_OVERVOLTAGE : 61|1@1+ (1,0) [0|1] "Bool" Vector__XXX

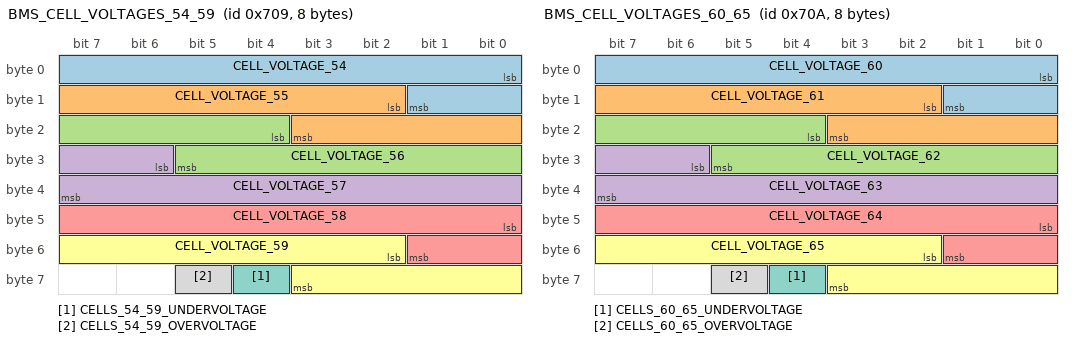
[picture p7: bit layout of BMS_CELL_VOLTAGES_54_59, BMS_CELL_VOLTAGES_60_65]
BO_ 1801 BMS_CELL_VOLTAGES_54_59: 8 BMS
 SG_ CELL_VOLTAGE_54 : 0|10@1+ (0.0078125,0) [0|8] "V" Vector__XXX
 SG_ CELL_VOLTAGE_55 : 10|10@1+ (0.0078125,0) [0|8] "V" Vector__XXX
 SG_ CELL_VOLTAGE_56 : 20|10@1+ (0.0078125,0) [0|8] "V" Vector__XXX
 SG_ CELL_VOLTAGE_57 : 30|10@1+ (0.0078125,0) [0|8] "V" Vector__XXX
 SG_ CELL_VOLTAGE_58 : 40|10@1+ (0.0078125,0) [0|8] "V" Vector__XXX
 SG_ CELL_VOLTAGE_59 : 50|10@1+ (0.0078125,0) [0|8] "V" Vector__XXX
 SG_ CELLS_54_59_UNDERVOLTAGE : 60|1@1+ (1,0) [0|1] "Bool" Vector__XXX
 SG_ CELLS_54_59_OVERVOLTAGE : 61|1@1+ (1,0) [0|1] "Bool" Vector__XXX

BO_ 1802 BMS_CELL_VOLTAGES_60_65: 8 BMS
 SG_ CELL_VOLTAGE_60 : 0|10@1+ (0.0078125,0) [0|8] "V" Vector__XXX
 SG_ CELL_VOLTAGE_61 : 10|10@1+ (0.0078125,0) [0|8] "V" Vector__XXX
 SG_ CELL_VOLTAGE_62 : 20|10@1+ (0.0078125,0) [0|8] "V" Vector__XXX
 SG_ CELL_VOLTAGE_63 : 30|10@1+ (0.0078125,0) [0|8] "V" Vector__XXX
 SG_ CELL_VOLTAGE_64 : 40|10@1+ (0.0078125,0) [0|8] "V" Vector__XXX
 SG_ CELL_VOLTAGE_65 : 50|10@1+ (0.0078125,0) [0|8] "V" Vector__XXX
 SG_ CELLS_60_65_UNDERVOLTAGE : 60|1@1+ (1,0) [0|1] "Bool" Vector__XXX
 SG_ CELLS_60_65_OVERVOLTAGE : 61|1@1+ (1,0) [0|1] "Bool" Vector__XXX

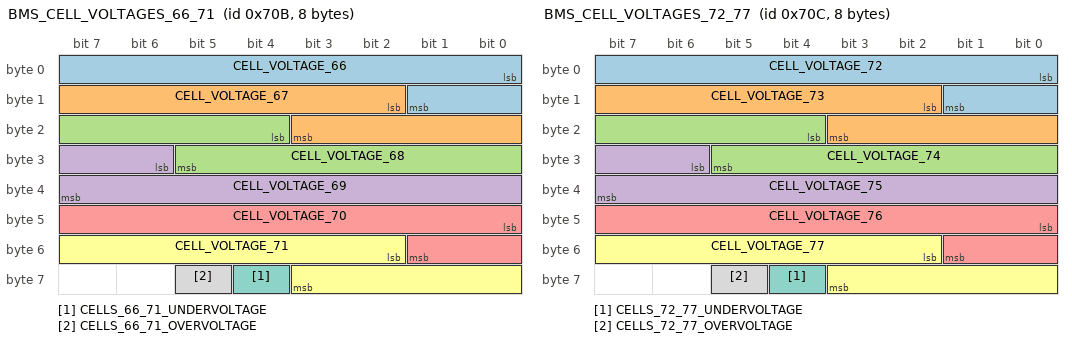
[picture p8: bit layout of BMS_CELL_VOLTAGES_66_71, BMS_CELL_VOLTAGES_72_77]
BO_ 1803 BMS_CELL_VOLTAGES_66_71: 8 BMS
 SG_ CELL_VOLTAGE_66 : 0|10@1+ (0.0078125,0) [0|8] "V" Vector__XXX
 SG_ CELL_VOLTAGE_67 : 10|10@1+ (0.0078125,0) [0|8] "V" Vector__XXX
 SG_ CELL_VOLTAGE_68 : 20|10@1+ (0.0078125,0) [0|8] "V" Vector__XXX
 SG_ CELL_VOLTAGE_69 : 30|10@1+ (0.0078125,0) [0|8] "V" Vector__XXX
 SG_ CELL_VOLTAGE_70 : 40|10@1+ (0.0078125,0) [0|8] "V" Vector__XXX
 SG_ CELL_VOLTAGE_71 : 50|10@1+ (0.0078125,0) [0|8] "V" Vector__XXX
 SG_ CELLS_66_71_UNDERVOLTAGE : 60|1@1+ (1,0) [0|1] "Bool" Vector__XXX
 SG_ CELLS_66_71_OVERVOLTAGE : 61|1@1+ (1,0) [0|1] "Bool" Vector__XXX

BO_ 1804 BMS_CELL_VOLTAGES_72_77: 8 BMS
 SG_ CELL_VOLTAGE_72 : 0|10@1+ (0.0078125,0) [0|8] "V" Vector__XXX
 SG_ CELL_VOLTAGE_73 : 10|10@1+ (0.0078125,0) [0|8] "V" Vector__XXX
 SG_ CELL_VOLTAGE_74 : 20|10@1+ (0.0078125,0) [0|8] "V" Vector__XXX
 SG_ CELL_VOLTAGE_75 : 30|10@1+ (0.0078125,0) [0|8] "V" Vector__XXX
 SG_ CELL_VOLTAGE_76 : 40|10@1+ (0.0078125,0) [0|8] "V" Vector__XXX
 SG_ CELL_VOLTAGE_77 : 50|10@1+ (0.0078125,0) [0|8] "V" Vector__XXX
 SG_ CELLS_72_77_UNDERVOLTAGE : 60|1@1+ (1,0) [0|1] "Bool" Vector__XXX
 SG_ CELLS_72_77_OVERVOLTAGE : 61|1@1+ (1,0) [0|1] "Bool" Vector__XXX

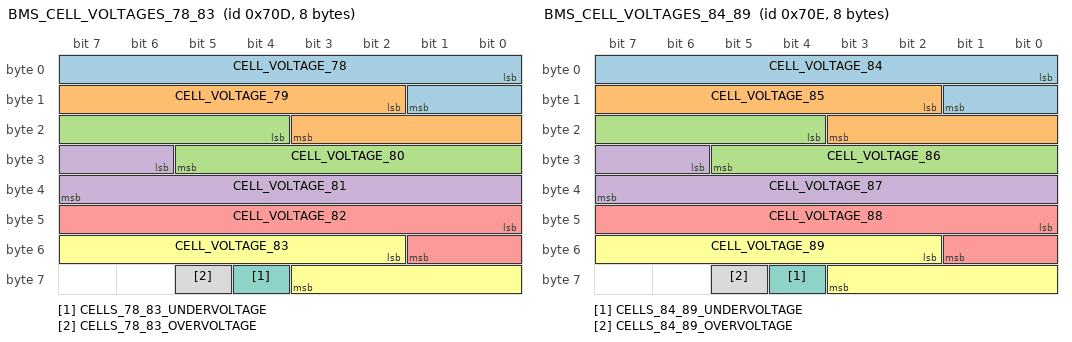
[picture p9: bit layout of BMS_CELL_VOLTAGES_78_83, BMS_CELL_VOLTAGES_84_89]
BO_ 1805 BMS_CELL_VOLTAGES_78_83: 8 BMS
 SG_ CELL_VOLTAGE_78 : 0|10@1+ (0.0078125,0) [0|8] "V" Vector__XXX
 SG_ CELL_VOLTAGE_79 : 10|10@1+ (0.0078125,0) [0|8] "V" Vector__XXX
 SG_ CELL_VOLTAGE_80 : 20|10@1+ (0.0078125,0) [0|8] "V" Vector__XXX
 SG_ CELL_VOLTAGE_81 : 30|10@1+ (0.0078125,0) [0|8] "V" Vector__XXX
 SG_ CELL_VOLTAGE_82 : 40|10@1+ (0.0078125,0) [0|8] "V" Vector__XXX
 SG_ CELL_VOLTAGE_83 : 50|10@1+ (0.0078125,0) [0|8] "V" Vector__XXX
 SG_ CELLS_78_83_UNDERVOLTAGE : 60|1@1+ (1,0) [0|1] "Bool" Vector__XXX
 SG_ CELLS_78_83_OVERVOLTAGE : 61|1@1+ (1,0) [0|1] "Bool" Vector__XXX

BO_ 1806 BMS_CELL_VOLTAGES_84_89: 8 BMS
 SG_ CELL_VOLTAGE_84 : 0|10@1+ (0.0078125,0) [0|8] "V" Vector__XXX
 SG_ CELL_VOLTAGE_85 : 10|10@1+ (0.0078125,0) [0|8] "V" Vector__XXX
 SG_ CELL_VOLTAGE_86 : 20|10@1+ (0.0078125,0) [0|8] "V" Vector__XXX
 SG_ CELL_VOLTAGE_87 : 30|10@1+ (0.0078125,0) [0|8] "V" Vector__XXX
 SG_ CELL_VOLTAGE_88 : 40|10@1+ (0.0078125,0) [0|8] "V" Vector__XXX
 SG_ CELL_VOLTAGE_89 : 50|10@1+ (0.0078125,0) [0|8] "V" Vector__XXX
 SG_ CELLS_84_89_UNDERVOLTAGE : 60|1@1+ (1,0) [0|1] "Bool" Vector__XXX
 SG_ CELLS_84_89_OVERVOLTAGE : 61|1@1+ (1,0) [0|1] "Bool" Vector__XXX

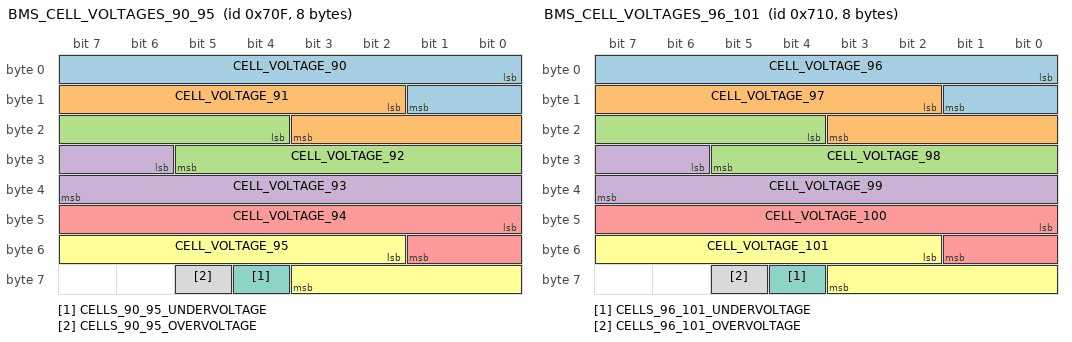
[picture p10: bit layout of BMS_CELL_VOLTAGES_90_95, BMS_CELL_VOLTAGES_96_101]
BO_ 1807 BMS_CELL_VOLTAGES_90_95: 8 BMS
 SG_ CELL_VOLTAGE_90 : 0|10@1+ (0.0078125,0) [0|8] "V" Vector__XXX
 SG_ CELL_VOLTAGE_91 : 10|10@1+ (0.0078125,0) [0|8] "V" Vector__XXX
 SG_ CELL_VOLTAGE_92 : 20|10@1+ (0.0078125,0) [0|8] "V" Vector__XXX
 SG_ CELL_VOLTAGE_93 : 30|10@1+ (0.0078125,0) [0|8] "V" Vector__XXX
 SG_ CELL_VOLTAGE_94 : 40|10@1+ (0.0078125,0) [0|8] "V" Vector__XXX
 SG_ CELL_VOLTAGE_95 : 50|10@1+ (0.0078125,0) [0|8] "V" Vector__XXX
 SG_ CELLS_90_95_UNDERVOLTAGE : 60|1@1+ (1,0) [0|1] "Bool" Vector__XXX
 SG_ CELLS_90_95_OVERVOLTAGE : 61|1@1+ (1,0) [0|1] "Bool" Vector__XXX

BO_ 1808 BMS_CELL_VOLTAGES_96_101: 8 BMS
 SG_ CELL_VOLTAGE_96 : 0|10@1+ (0.0078125,0) [0|8] "V" Vector__XXX
 SG_ CELL_VOLTAGE_97 : 10|10@1+ (0.0078125,0) [0|8] "V" Vector__XXX
 SG_ CELL_VOLTAGE_98 : 20|10@1+ (0.0078125,0) [0|8] "V" Vector__XXX
 SG_ CELL_VOLTAGE_99 : 30|10@1+ (0.0078125,0) [0|8] "V" Vector__XXX
 SG_ CELL_VOLTAGE_100 : 40|10@1+ (0.0078125,0) [0|8] "V" Vector__XXX
 SG_ CELL_VOLTAGE_101 : 50|10@1+ (0.0078125,0) [0|8] "V" Vector__XXX
 SG_ CELLS_96_101_UNDERVOLTAGE : 60|1@1+ (1,0) [0|1] "Bool" Vector__XXX
 SG_ CELLS_96_101_OVERVOLTAGE : 61|1@1+ (1,0) [0|1] "Bool" Vector__XXX

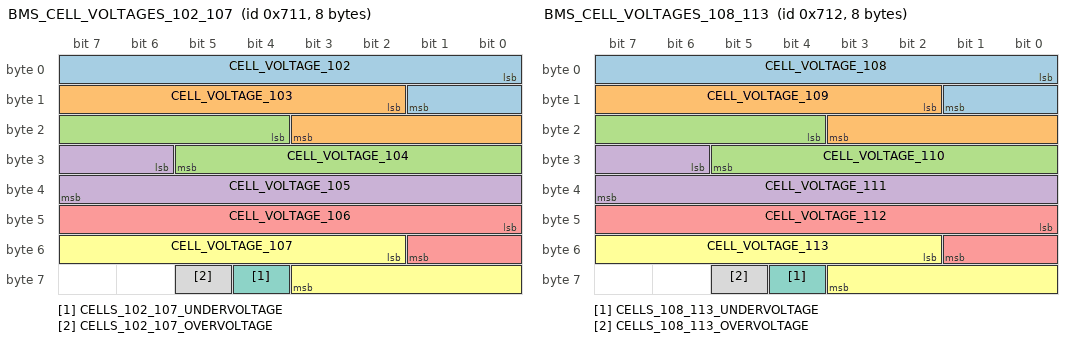
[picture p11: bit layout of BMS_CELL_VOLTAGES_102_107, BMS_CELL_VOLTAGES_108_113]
BO_ 1809 BMS_CELL_VOLTAGES_102_107: 8 BMS
 SG_ CELL_VOLTAGE_102 : 0|10@1+ (0.0078125,0) [0|8] "V" Vector__XXX
 SG_ CELL_VOLTAGE_103 : 10|10@1+ (0.0078125,0) [0|8] "V" Vector__XXX
 SG_ CELL_VOLTAGE_104 : 20|10@1+ (0.0078125,0) [0|8] "V" Vector__XXX
 SG_ CELL_VOLTAGE_105 : 30|10@1+ (0.0078125,0) [0|8] "V" Vector__XXX
 SG_ CELL_VOLTAGE_106 : 40|10@1+ (0.0078125,0) [0|8] "V" Vector__XXX
 SG_ CELL_VOLTAGE_107 : 50|10@1+ (0.0078125,0) [0|8] "V" Vector__XXX
 SG_ CELLS_102_107_UNDERVOLTAGE : 60|1@1+ (1,0) [0|1] "Bool" Vector__XXX
 SG_ CELLS_102_107_OVERVOLTAGE : 61|1@1+ (1,0) [0|1] "Bool" Vector__XXX

BO_ 1810 BMS_CELL_VOLTAGES_108_113: 8 BMS
 SG_ CELL_VOLTAGE_108 : 0|10@1+ (0.0078125,0) [0|8] "V" Vector__XXX
 SG_ CELL_VOLTAGE_109 : 10|10@1+ (0.0078125,0) [0|8] "V" Vector__XXX
 SG_ CELL_VOLTAGE_110 : 20|10@1+ (0.0078125,0) [0|8] "V" Vector__XXX
 SG_ CELL_VOLTAGE_111 : 30|10@1+ (0.0078125,0) [0|8] "V" Vector__XXX
 SG_ CELL_VOLTAGE_112 : 40|10@1+ (0.0078125,0) [0|8] "V" Vector__XXX
 SG_ CELL_VOLTAGE_113 : 50|10@1+ (0.0078125,0) [0|8] "V" Vector__XXX
 SG_ CELLS_108_113_UNDERVOLTAGE : 60|1@1+ (1,0) [0|1] "Bool" Vector__XXX
 SG_ CELLS_108_113_OVERVOLTAGE : 61|1@1+ (1,0) [0|1] "Bool" Vector__XXX

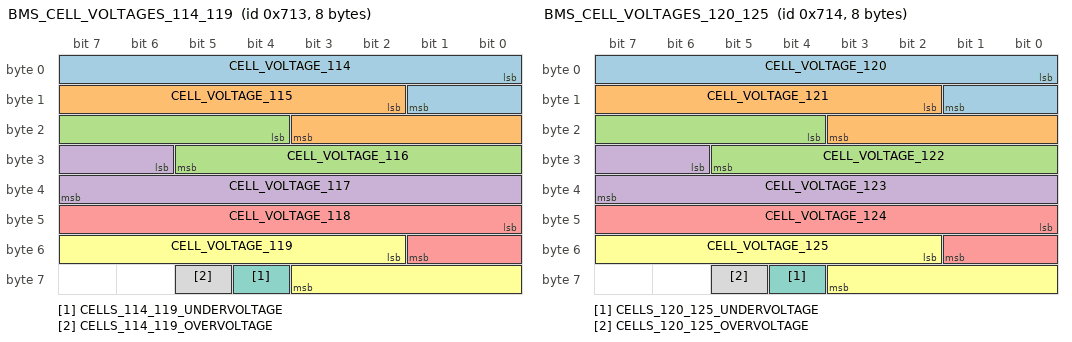
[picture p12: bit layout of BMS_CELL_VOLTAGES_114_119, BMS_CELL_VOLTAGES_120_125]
BO_ 1811 BMS_CELL_VOLTAGES_114_119: 8 BMS
 SG_ CELL_VOLTAGE_114 : 0|10@1+ (0.0078125,0) [0|8] "V" Vector__XXX
 SG_ CELL_VOLTAGE_115 : 10|10@1+ (0.0078125,0) [0|8] "V" Vector__XXX
 SG_ CELL_VOLTAGE_116 : 20|10@1+ (0.0078125,0) [0|8] "V" Vector__XXX
 SG_ CELL_VOLTAGE_117 : 30|10@1+ (0.0078125,0) [0|8] "V" Vector__XXX
 SG_ CELL_VOLTAGE_118 : 40|10@1+ (0.0078125,0) [0|8] "V" Vector__XXX
 SG_ CELL_VOLTAGE_119 : 50|10@1+ (0.0078125,0) [0|8] "V" Vector__XXX
 SG_ CELLS_114_119_UNDERVOLTAGE : 60|1@1+ (1,0) [0|1] "Bool" Vector__XXX
 SG_ CELLS_114_119_OVERVOLTAGE : 61|1@1+ (1,0) [0|1] "Bool" Vector__XXX

BO_ 1812 BMS_CELL_VOLTAGES_120_125: 8 BMS
 SG_ CELL_VOLTAGE_120 : 0|10@1+ (0.0078125,0) [0|8] "V" Vector__XXX
 SG_ CELL_VOLTAGE_121 : 10|10@1+ (0.0078125,0) [0|8] "V" Vector__XXX
 SG_ CELL_VOLTAGE_122 : 20|10@1+ (0.0078125,0) [0|8] "V" Vector__XXX
 SG_ CELL_VOLTAGE_123 : 30|10@1+ (0.0078125,0) [0|8] "V" Vector__XXX
 SG_ CELL_VOLTAGE_124 : 40|10@1+ (0.0078125,0) [0|8] "V" Vector__XXX
 SG_ CELL_VOLTAGE_125 : 50|10@1+ (0.0078125,0) [0|8] "V" Vector__XXX
 SG_ CELLS_120_125_UNDERVOLTAGE : 60|1@1+ (1,0) [0|1] "Bool" Vector__XXX
 SG_ CELLS_120_125_OVERVOLTAGE : 61|1@1+ (1,0) [0|1] "Bool" Vector__XXX

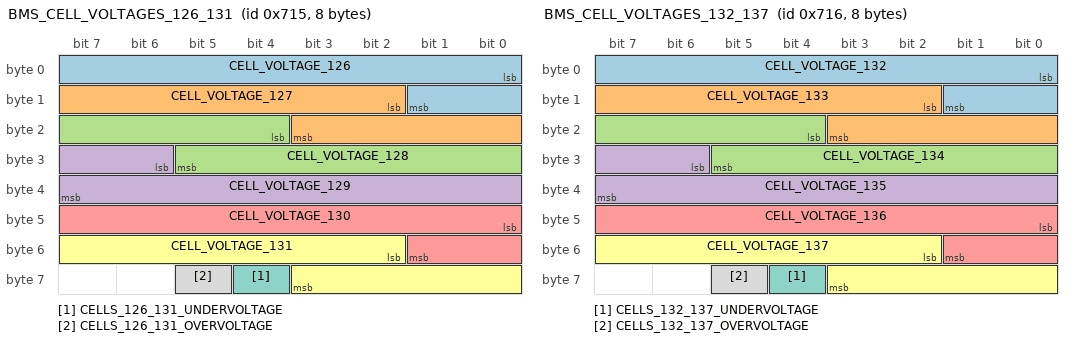
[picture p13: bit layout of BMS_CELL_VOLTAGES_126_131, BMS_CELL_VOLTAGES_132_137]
BO_ 1813 BMS_CELL_VOLTAGES_126_131: 8 BMS
 SG_ CELL_VOLTAGE_126 : 0|10@1+ (0.0078125,0) [0|8] "V" Vector__XXX
 SG_ CELL_VOLTAGE_127 : 10|10@1+ (0.0078125,0) [0|8] "V" Vector__XXX
 SG_ CELL_VOLTAGE_128 : 20|10@1+ (0.0078125,0) [0|8] "V" Vector__XXX
 SG_ CELL_VOLTAGE_129 : 30|10@1+ (0.0078125,0) [0|8] "V" Vector__XXX
 SG_ CELL_VOLTAGE_130 : 40|10@1+ (0.0078125,0) [0|8] "V" Vector__XXX
 SG_ CELL_VOLTAGE_131 : 50|10@1+ (0.0078125,0) [0|8] "V" Vector__XXX
 SG_ CELLS_126_131_UNDERVOLTAGE : 60|1@1+ (1,0) [0|1] "Bool" Vector__XXX
 SG_ CELLS_126_131_OVERVOLTAGE : 61|1@1+ (1,0) [0|1] "Bool" Vector__XXX

BO_ 1814 BMS_CELL_VOLTAGES_132_137: 8 BMS
 SG_ CELL_VOLTAGE_132 : 0|10@1+ (0.0078125,0) [0|8] "V" Vector__XXX
 SG_ CELL_VOLTAGE_133 : 10|10@1+ (0.0078125,0) [0|8] "V" Vector__XXX
 SG_ CELL_VOLTAGE_134 : 20|10@1+ (0.0078125,0) [0|8] "V" Vector__XXX
 SG_ CELL_VOLTAGE_135 : 30|10@1+ (0.0078125,0) [0|8] "V" Vector__XXX
 SG_ CELL_VOLTAGE_136 : 40|10@1+ (0.0078125,0) [0|8] "V" Vector__XXX
 SG_ CELL_VOLTAGE_137 : 50|10@1+ (0.0078125,0) [0|8] "V" Vector__XXX
 SG_ CELLS_132_137_UNDERVOLTAGE : 60|1@1+ (1,0) [0|1] "Bool" Vector__XXX
 SG_ CELLS_132_137_OVERVOLTAGE : 61|1@1+ (1,0) [0|1] "Bool" Vector__XXX

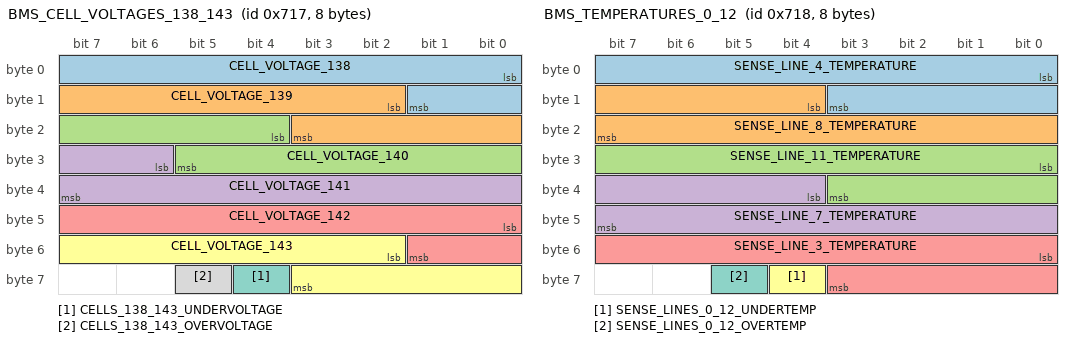
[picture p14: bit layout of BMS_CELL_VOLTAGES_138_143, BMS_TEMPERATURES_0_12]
BO_ 1815 BMS_CELL_VOLTAGES_138_143: 8 BMS
 SG_ CELL_VOLTAGE_138 : 0|10@1+ (0.0078125,0) [0|8] "V" Vector__XXX
 SG_ CELL_VOLTAGE_139 : 10|10@1+ (0.0078125,0) [0|8] "V" Vector__XXX
 SG_ CELL_VOLTAGE_140 : 20|10@1+ (0.0078125,0) [0|8] "V" Vector__XXX
 SG_ CELL_VOLTAGE_141 : 30|10@1+ (0.0078125,0) [0|8] "V" Vector__XXX
 SG_ CELL_VOLTAGE_142 : 40|10@1+ (0.0078125,0) [0|8] "V" Vector__XXX
 SG_ CELL_VOLTAGE_143 : 50|10@1+ (0.0078125,0) [0|8] "V" Vector__XXX
 SG_ CELLS_138_143_UNDERVOLTAGE : 60|1@1+ (1,0) [0|1] "Bool" Vector__XXX
 SG_ CELLS_138_143_OVERVOLTAGE : 61|1@1+ (1,0) [0|1] "Bool" Vector__XXX

BO_ 1816 BMS_TEMPERATURES_0_12: 8 BMS
 SG_ SENSE_LINE_4_TEMPERATURE : 0|12@1+ (0.0625,-106) [-106|150] "C" Vector__XXX
 SG_ SENSE_LINE_8_TEMPERATURE : 12|12@1+ (0.0625,-106) [-106|150] "C" Vector__XXX
 SG_ SENSE_LINE_11_TEMPERATURE : 24|12@1+ (0.0625,-106) [-106|150] "C" Vector__XXX
 SG_ SENSE_LINE_7_TEMPERATURE : 36|12@1+ (0.0625,-106) [-106|150] "C" Vector__XXX
 SG_ SENSE_LINE_3_TEMPERATURE : 48|12@1+ (0.0625,-106) [-106|150] "C" Vector__XXX
 SG_ SENSE_LINES_0_12_UNDERTEMP : 60|1@1+ (1,0) [0|1] "Bool" Vector__XXX
 SG_ SENSE_LINES_0_12_OVERTEMP : 61|1@1+ (1,0) [0|1] "Bool" Vector__XXX

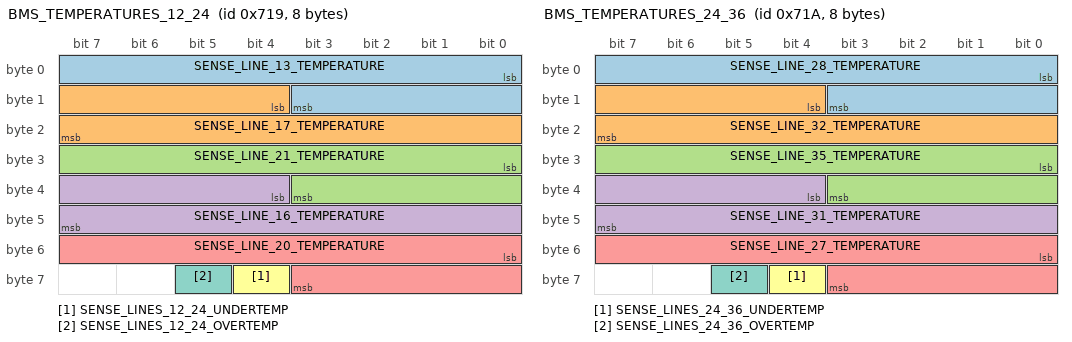
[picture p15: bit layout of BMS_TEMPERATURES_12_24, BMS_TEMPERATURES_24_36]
BO_ 1817 BMS_TEMPERATURES_12_24: 8 BMS
 SG_ SENSE_LINE_13_TEMPERATURE : 0|12@1+ (0.0625,-106) [-106|150] "C" Vector__XXX
 SG_ SENSE_LINE_17_TEMPERATURE : 12|12@1+ (0.0625,-106) [-106|150] "C" Vector__XXX
 SG_ SENSE_LINE_21_TEMPERATURE : 24|12@1+ (0.0625,-106) [-106|150] "C" Vector__XXX
 SG_ SENSE_LINE_16_TEMPERATURE : 36|12@1+ (0.0625,-106) [-106|150] "C" Vector__XXX
 SG_ SENSE_LINE_20_TEMPERATURE : 48|12@1+ (0.0625,-106) [-106|150] "C" Vector__XXX
 SG_ SENSE_LINES_12_24_UNDERTEMP : 60|1@1+ (1,0) [0|1] "Bool" Vector__XXX
 SG_ SENSE_LINES_12_24_OVERTEMP : 61|1@1+ (1,0) [0|1] "Bool" Vector__XXX

BO_ 1818 BMS_TEMPERATURES_24_36: 8 BMS
 SG_ SENSE_LINE_28_TEMPERATURE : 0|12@1+ (0.0625,-106) [-106|150] "C" Vector__XXX
 SG_ SENSE_LINE_32_TEMPERATURE : 12|12@1+ (0.0625,-106) [-106|150] "C" Vector__XXX
 SG_ SENSE_LINE_35_TEMPERATURE : 24|12@1+ (0.0625,-106) [-106|150] "C" Vector__XXX
 SG_ SENSE_LINE_31_TEMPERATURE : 36|12@1+ (0.0625,-106) [-106|150] "C" Vector__XXX
 SG_ SENSE_LINE_27_TEMPERATURE : 48|12@1+ (0.0625,-106) [-106|150] "C" Vector__XXX
 SG_ SENSE_LINES_24_36_UNDERTEMP : 60|1@1+ (1,0) [0|1] "Bool" Vector__XXX
 SG_ SENSE_LINES_24_36_OVERTEMP : 61|1@1+ (1,0) [0|1] "Bool" Vector__XXX

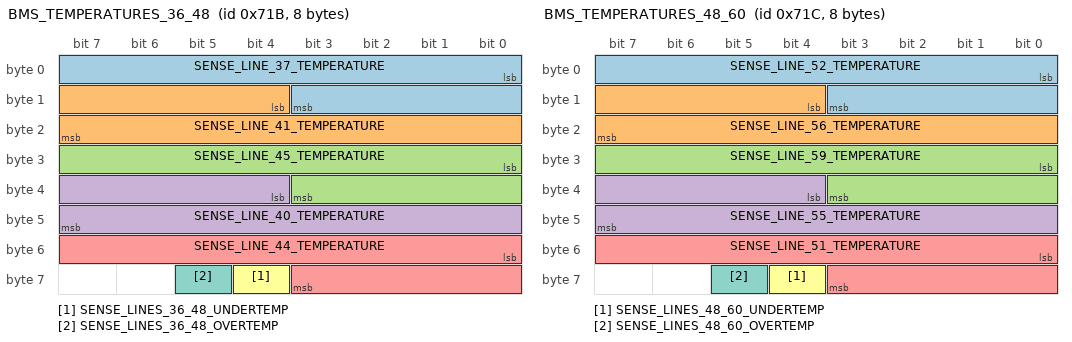
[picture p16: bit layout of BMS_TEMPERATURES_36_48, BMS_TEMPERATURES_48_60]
BO_ 1819 BMS_TEMPERATURES_36_48: 8 BMS
 SG_ SENSE_LINE_37_TEMPERATURE : 0|12@1+ (0.0625,-106) [-106|150] "C" Vector__XXX
 SG_ SENSE_LINE_41_TEMPERATURE : 12|12@1+ (0.0625,-106) [-106|150] "C" Vector__XXX
 SG_ SENSE_LINE_45_TEMPERATURE : 24|12@1+ (0.0625,-106) [-106|150] "C" Vector__XXX
 SG_ SENSE_LINE_40_TEMPERATURE : 36|12@1+ (0.0625,-106) [-106|150] "C" Vector__XXX
 SG_ SENSE_LINE_44_TEMPERATURE : 48|12@1+ (0.0625,-106) [-106|150] "C" Vector__XXX
 SG_ SENSE_LINES_36_48_UNDERTEMP : 60|1@1+ (1,0) [0|1] "Bool" Vector__XXX
 SG_ SENSE_LINES_36_48_OVERTEMP : 61|1@1+ (1,0) [0|1] "Bool" Vector__XXX

BO_ 1820 BMS_TEMPERATURES_48_60: 8 BMS
 SG_ SENSE_LINE_52_TEMPERATURE : 0|12@1+ (0.0625,-106) [-106|150] "C" Vector__XXX
 SG_ SENSE_LINE_56_TEMPERATURE : 12|12@1+ (0.0625,-106) [-106|150] "C" Vector__XXX
 SG_ SENSE_LINE_59_TEMPERATURE : 24|12@1+ (0.0625,-106) [-106|150] "C" Vector__XXX
 SG_ SENSE_LINE_55_TEMPERATURE : 36|12@1+ (0.0625,-106) [-106|150] "C" Vector__XXX
 SG_ SENSE_LINE_51_TEMPERATURE : 48|12@1+ (0.0625,-106) [-106|150] "C" Vector__XXX
 SG_ SENSE_LINES_48_60_UNDERTEMP : 60|1@1+ (1,0) [0|1] "Bool" Vector__XXX
 SG_ SENSE_LINES_48_60_OVERTEMP : 61|1@1+ (1,0) [0|1] "Bool" Vector__XXX

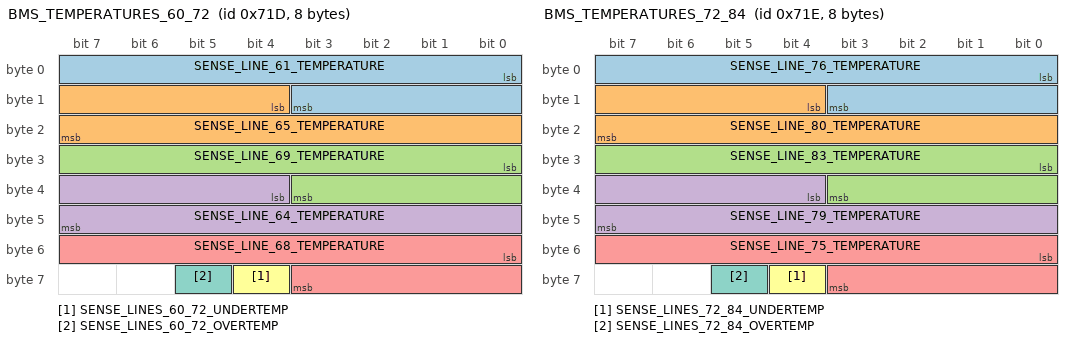
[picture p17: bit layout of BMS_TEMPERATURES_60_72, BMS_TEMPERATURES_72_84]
BO_ 1821 BMS_TEMPERATURES_60_72: 8 BMS
 SG_ SENSE_LINE_61_TEMPERATURE : 0|12@1+ (0.0625,-106) [-106|150] "C" Vector__XXX
 SG_ SENSE_LINE_65_TEMPERATURE : 12|12@1+ (0.0625,-106) [-106|150] "C" Vector__XXX
 SG_ SENSE_LINE_69_TEMPERATURE : 24|12@1+ (0.0625,-106) [-106|150] "C" Vector__XXX
 SG_ SENSE_LINE_64_TEMPERATURE : 36|12@1+ (0.0625,-106) [-106|150] "C" Vector__XXX
 SG_ SENSE_LINE_68_TEMPERATURE : 48|12@1+ (0.0625,-106) [-106|150] "C" Vector__XXX
 SG_ SENSE_LINES_60_72_UNDERTEMP : 60|1@1+ (1,0) [0|1] "Bool" Vector__XXX
 SG_ SENSE_LINES_60_72_OVERTEMP : 61|1@1+ (1,0) [0|1] "Bool" Vector__XXX

BO_ 1822 BMS_TEMPERATURES_72_84: 8 BMS
 SG_ SENSE_LINE_76_TEMPERATURE : 0|12@1+ (0.0625,-106) [-106|150] "C" Vector__XXX
 SG_ SENSE_LINE_80_TEMPERATURE : 12|12@1+ (0.0625,-106) [-106|150] "C" Vector__XXX
 SG_ SENSE_LINE_83_TEMPERATURE : 24|12@1+ (0.0625,-106) [-106|150] "C" Vector__XXX
 SG_ SENSE_LINE_79_TEMPERATURE : 36|12@1+ (0.0625,-106) [-106|150] "C" Vector__XXX
 SG_ SENSE_LINE_75_TEMPERATURE : 48|12@1+ (0.0625,-106) [-106|150] "C" Vector__XXX
 SG_ SENSE_LINES_72_84_UNDERTEMP : 60|1@1+ (1,0) [0|1] "Bool" Vector__XXX
 SG_ SENSE_LINES_72_84_OVERTEMP : 61|1@1+ (1,0) [0|1] "Bool" Vector__XXX

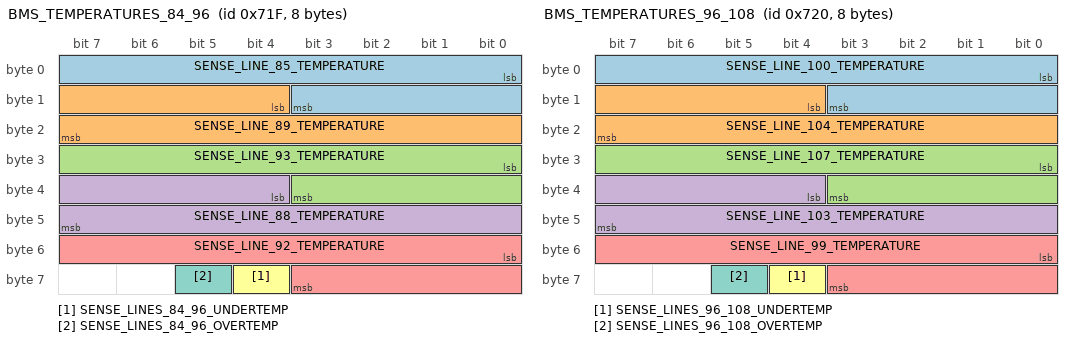
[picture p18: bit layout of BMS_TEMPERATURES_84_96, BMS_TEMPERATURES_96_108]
BO_ 1823 BMS_TEMPERATURES_84_96: 8 BMS
 SG_ SENSE_LINE_85_TEMPERATURE : 0|12@1+ (0.0625,-106) [-106|150] "C" Vector__XXX
 SG_ SENSE_LINE_89_TEMPERATURE : 12|12@1+ (0.0625,-106) [-106|150] "C" Vector__XXX
 SG_ SENSE_LINE_93_TEMPERATURE : 24|12@1+ (0.0625,-106) [-106|150] "C" Vector__XXX
 SG_ SENSE_LINE_88_TEMPERATURE : 36|12@1+ (0.0625,-106) [-106|150] "C" Vector__XXX
 SG_ SENSE_LINE_92_TEMPERATURE : 48|12@1+ (0.0625,-106) [-106|150] "C" Vector__XXX
 SG_ SENSE_LINES_84_96_UNDERTEMP : 60|1@1+ (1,0) [0|1] "Bool" Vector__XXX
 SG_ SENSE_LINES_84_96_OVERTEMP : 61|1@1+ (1,0) [0|1] "Bool" Vector__XXX

BO_ 1824 BMS_TEMPERATURES_96_108: 8 BMS
 SG_ SENSE_LINE_100_TEMPERATURE : 0|12@1+ (0.0625,-106) [-106|150] "C" Vector__XXX
 SG_ SENSE_LINE_104_TEMPERATURE : 12|12@1+ (0.0625,-106) [-106|150] "C" Vector__XXX
 SG_ SENSE_LINE_107_TEMPERATURE : 24|12@1+ (0.0625,-106) [-106|150] "C" Vector__XXX
 SG_ SENSE_LINE_103_TEMPERATURE : 36|12@1+ (0.0625,-106) [-106|150] "C" Vector__XXX
 SG_ SENSE_LINE_99_TEMPERATURE : 48|12@1+ (0.0625,-106) [-106|150] "C" Vector__XXX
 SG_ SENSE_LINES_96_108_UNDERTEMP : 60|1@1+ (1,0) [0|1] "Bool" Vector__XXX
 SG_ SENSE_LINES_96_108_OVERTEMP : 61|1@1+ (1,0) [0|1] "Bool" Vector__XXX

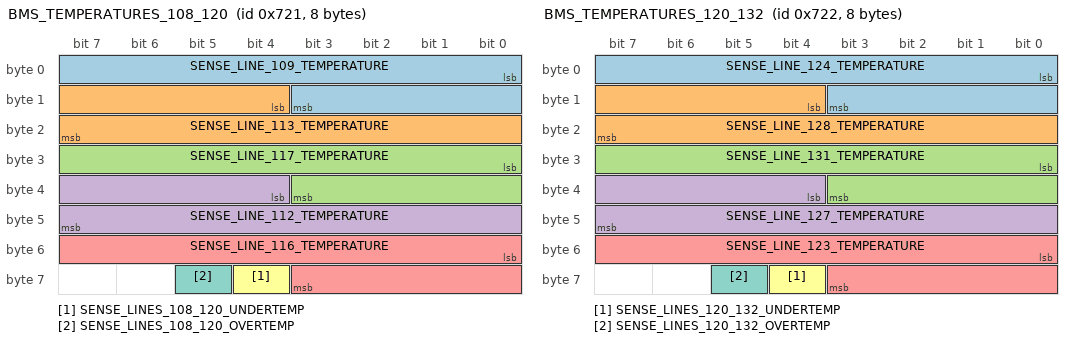
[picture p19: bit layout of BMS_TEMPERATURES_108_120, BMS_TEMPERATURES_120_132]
BO_ 1825 BMS_TEMPERATURES_108_120: 8 BMS
 SG_ SENSE_LINE_109_TEMPERATURE : 0|12@1+ (0.0625,-106) [-106|150] "C" Vector__XXX
 SG_ SENSE_LINE_113_TEMPERATURE : 12|12@1+ (0.0625,-106) [-106|150] "C" Vector__XXX
 SG_ SENSE_LINE_117_TEMPERATURE : 24|12@1+ (0.0625,-106) [-106|150] "C" Vector__XXX
 SG_ SENSE_LINE_112_TEMPERATURE : 36|12@1+ (0.0625,-106) [-106|150] "C" Vector__XXX
 SG_ SENSE_LINE_116_TEMPERATURE : 48|12@1+ (0.0625,-106) [-106|150] "C" Vector__XXX
 SG_ SENSE_LINES_108_120_UNDERTEMP : 60|1@1+ (1,0) [0|1] "Bool" Vector__XXX
 SG_ SENSE_LINES_108_120_OVERTEMP : 61|1@1+ (1,0) [0|1] "Bool" Vector__XXX

BO_ 1826 BMS_TEMPERATURES_120_132: 8 BMS
 SG_ SENSE_LINE_124_TEMPERATURE : 0|12@1+ (0.0625,-106) [-106|150] "C" Vector__XXX
 SG_ SENSE_LINE_128_TEMPERATURE : 12|12@1+ (0.0625,-106) [-106|150] "C" Vector__XXX
 SG_ SENSE_LINE_131_TEMPERATURE : 24|12@1+ (0.0625,-106) [-106|150] "C" Vector__XXX
 SG_ SENSE_LINE_127_TEMPERATURE : 36|12@1+ (0.0625,-106) [-106|150] "C" Vector__XXX
 SG_ SENSE_LINE_123_TEMPERATURE : 48|12@1+ (0.0625,-106) [-106|150] "C" Vector__XXX
 SG_ SENSE_LINES_120_132_UNDERTEMP : 60|1@1+ (1,0) [0|1] "Bool" Vector__XXX
 SG_ SENSE_LINES_120_132_OVERTEMP : 61|1@1+ (1,0) [0|1] "Bool" Vector__XXX

BO_ 1827 BMS_TEMPERATURES_132_144: 8 BMS
 SG_ SENSE_LINE_133_TEMPERATURE : 0|12@1+ (0.0625,-106) [-106|150] "C" Vector__XXX
 SG_ SENSE_LINE_137_TEMPERATURE : 12|12@1+ (0.0625,-106) [-106|150] "C" Vector__XXX
 SG_ SENSE_LINE_141_TEMPERATURE : 24|12@1+ (0.0625,-106) [-106|150] "C" Vector__XXX
 SG_ SENSE_LINE_136_TEMPERATURE : 36|12@1+ (0.0625,-106) [-106|150] "C" Vector__XXX
 SG_ SENSE_LINE_140_TEMPERATURE : 48|12@1+ (0.0625,-106) [-106|150] "C" Vector__XXX
 SG_ SENSE_LINES_132_144_UNDERTEMP : 60|1@1+ (1,0) [0|1] "Bool" Vector__XXX
 SG_ SENSE_LINES_132_144_OVERTEMP : 61|1@1+ (1,0) [0|1] "Bool" Vector__XXX

BO_ 1828 BMS_SENSE_LINE_STATUSES_0_48: 8 BMS
 SG_ SENSE_LINE_0_HI_OPEN : 0|1@1+ (1,0) [0|1] "Bool" Vector__XXX
 SG_ SENSE_LINE_1_OPEN : 1|1@1+ (1,0) [0|1] "Bool" Vector__XXX
 SG_ SENSE_LINE_2_OPEN : 2|1@1+ (1,0) [0|1] "Bool" Vector__XXX
 SG_ SENSE_LINE_3_OPEN : 3|1@1+ (1,0) [0|1] "Bool" Vector__XXX
 SG_ SENSE_LINE_4_OPEN : 4|1@1+ (1,0) [0|1] "Bool" Vector__XXX
 SG_ SENSE_LINE_5_OPEN : 5|1@1+ (1,0) [0|1] "Bool" Vector__XXX
 SG_ SENSE_LINE_6_OPEN : 6|1@1+ (1,0) [0|1] "Bool" Vector__XXX
 SG_ SENSE_LINE_7_OPEN : 7|1@1+ (1,0) [0|1] "Bool" Vector__XXX
 SG_ SENSE_LINE_8_OPEN : 8|1@1+ (1,0) [0|1] "Bool" Vector__XXX
 SG_ SENSE_LINE_9_OPEN : 9|1@1+ (1,0) [0|1] "Bool" Vector__XXX
 SG_ SENSE_LINE_10_OPEN : 10|1@1+ (1,0) [0|1] "Bool" Vector__XXX
 SG_ SENSE_LINE_11_OPEN : 11|1@1+ (1,0) [0|1] "Bool" Vector__XXX
 SG_ SENSE_LINE_12_LO_OPEN : 12|1@1+ (1,0) [0|1] "Bool" Vector__XXX
 SG_ SENSE_LINE_12_HI_OPEN : 16|1@1+ (1,0) [0|1] "Bool" Vector__XXX
 SG_ SENSE_LINE_13_OPEN : 17|1@1+ (1,0) [0|1] "Bool" Vector__XXX
 SG_ SENSE_LINE_14_OPEN : 18|1@1+ (1,0) [0|1] "Bool" Vector__XXX
 SG_ SENSE_LINE_15_OPEN : 19|1@1+ (1,0) [0|1] "Bool" Vector__XXX
 SG_ SENSE_LINE_16_OPEN : 20|1@1+ (1,0) [0|1] "Bool" Vector__XXX
 SG_ SENSE_LINE_17_OPEN : 21|1@1+ (1,0) [0|1] "Bool" Vector__XXX
 SG_ SENSE_LINE_18_OPEN : 22|1@1+ (1,0) [0|1] "Bool" Vector__XXX
 SG_ SENSE_LINE_19_OPEN : 23|1@1+ (1,0) [0|1] "Bool" Vector__XXX
 SG_ SENSE_LINE_20_OPEN : 24|1@1+ (1,0) [0|1] "Bool" Vector__XXX
 SG_ SENSE_LINE_21_OPEN : 25|1@1+ (1,0) [0|1] "Bool" Vector__XXX
 SG_ SENSE_LINE_22_OPEN : 26|1@1+ (1,0) [0|1] "Bool" Vector__XXX
 SG_ SENSE_LINE_23_OPEN : 27|1@1+ (1,0) [0|1] "Bool" Vector__XXX
 SG_ SENSE_LINE_24_LO_OPEN : 28|1@1+ (1,0) [0|1] "Bool" Vector__XXX
 SG_ SENSE_LINE_24_HI_OPEN : 32|1@1+ (1,0) [0|1] "Bool" Vector__XXX
 SG_ SENSE_LINE_25_OPEN : 33|1@1+ (1,0) [0|1] "Bool" Vector__XXX
 SG_ SENSE_LINE_26_OPEN : 34|1@1+ (1,0) [0|1] "Bool" Vector__XXX
 SG_ SENSE_LINE_27_OPEN : 35|1@1+ (1,0) [0|1] "Bool" Vector__XXX
 SG_ SENSE_LINE_28_OPEN : 36|1@1+ (1,0) [0|1] "Bool" Vector__XXX
 SG_ SENSE_LINE_29_OPEN : 37|1@1+ (1,0) [0|1] "Bool" Vector__XXX
 SG_ SENSE_LINE_30_OPEN : 38|1@1+ (1,0) [0|1] "Bool" Vector__XXX
 SG_ SENSE_LINE_31_OPEN : 39|1@1+ (1,0) [0|1] "Bool" Vector__XXX
 SG_ SENSE_LINE_32_OPEN : 40|1@1+ (1,0) [0|1] "Bool" Vector__XXX
 SG_ SENSE_LINE_33_OPEN : 41|1@1+ (1,0) [0|1] "Bool" Vector__XXX
 SG_ SENSE_LINE_34_OPEN : 42|1@1+ (1,0) [0|1] "Bool" Vector__XXX
 SG_ SENSE_LINE_35_OPEN : 43|1@1+ (1,0) [0|1] "Bool" Vector__XXX
 SG_ SENSE_LINE_36_LO_OPEN : 44|1@1+ (1,0) [0|1] "Bool" Vector__XXX
 SG_ SENSE_LINE_36_HI_OPEN : 48|1@1+ (1,0) [0|1] "Bool" Vector__XXX
 SG_ SENSE_LINE_37_OPEN : 49|1@1+ (1,0) [0|1] "Bool" Vector__XXX
 SG_ SENSE_LINE_38_OPEN : 50|1@1+ (1,0) [0|1] "Bool" Vector__XXX
 SG_ SENSE_LINE_39_OPEN : 51|1@1+ (1,0) [0|1] "Bool" Vector__XXX
 SG_ SENSE_LINE_40_OPEN : 52|1@1+ (1,0) [0|1] "Bool" Vector__XXX
 SG_ SENSE_LINE_41_OPEN : 53|1@1+ (1,0) [0|1] "Bool" Vector__XXX
 SG_ SENSE_LINE_42_OPEN : 54|1@1+ (1,0) [0|1] "Bool" Vector__XXX
 SG_ SENSE_LINE_43_OPEN : 55|1@1+ (1,0) [0|1] "Bool" Vector__XXX
 SG_ SENSE_LINE_44_OPEN : 56|1@1+ (1,0) [0|1] "Bool" Vector__XXX
 SG_ SENSE_LINE_45_OPEN : 57|1@1+ (1,0) [0|1] "Bool" Vector__XXX
 SG_ SENSE_LINE_46_OPEN : 58|1@1+ (1,0) [0|1] "Bool" Vector__XXX
 SG_ SENSE_LINE_47_OPEN : 59|1@1+ (1,0) [0|1] "Bool" Vector__XXX
 SG_ SENSE_LINE_48_LO_OPEN : 60|1@1+ (1,0) [0|1] "Bool" Vector__XXX

BO_ 1829 BMS_SENSE_LINE_STATUSES_48_96: 8 BMS
 SG_ SENSE_LINE_48_HI_OPEN : 0|1@1+ (1,0) [0|1] "Bool" Vector__XXX
 SG_ SENSE_LINE_49_OPEN : 1|1@1+ (1,0) [0|1] "Bool" Vector__XXX
 SG_ SENSE_LINE_50_OPEN : 2|1@1+ (1,0) [0|1] "Bool" Vector__XXX
 SG_ SENSE_LINE_51_OPEN : 3|1@1+ (1,0) [0|1] "Bool" Vector__XXX
 SG_ SENSE_LINE_52_OPEN : 4|1@1+ (1,0) [0|1] "Bool" Vector__XXX
 SG_ SENSE_LINE_53_OPEN : 5|1@1+ (1,0) [0|1] "Bool" Vector__XXX
 SG_ SENSE_LINE_54_OPEN : 6|1@1+ (1,0) [0|1] "Bool" Vector__XXX
 SG_ SENSE_LINE_55_OPEN : 7|1@1+ (1,0) [0|1] "Bool" Vector__XXX
 SG_ SENSE_LINE_56_OPEN : 8|1@1+ (1,0) [0|1] "Bool" Vector__XXX
 SG_ SENSE_LINE_57_OPEN : 9|1@1+ (1,0) [0|1] "Bool" Vector__XXX
 SG_ SENSE_LINE_58_OPEN : 10|1@1+ (1,0) [0|1] "Bool" Vector__XXX
 SG_ SENSE_LINE_59_OPEN : 11|1@1+ (1,0) [0|1] "Bool" Vector__XXX
 SG_ SENSE_LINE_60_LO_OPEN : 12|1@1+ (1,0) [0|1] "Bool" Vector__XXX
 SG_ SENSE_LINE_60_HI_OPEN : 16|1@1+ (1,0) [0|1] "Bool" Vector__XXX
 SG_ SENSE_LINE_61_OPEN : 17|1@1+ (1,0) [0|1] "Bool" Vector__XXX
 SG_ SENSE_LINE_62_OPEN : 18|1@1+ (1,0) [0|1] "Bool" Vector__XXX
 SG_ SENSE_LINE_63_OPEN : 19|1@1+ (1,0) [0|1] "Bool" Vector__XXX
 SG_ SENSE_LINE_64_OPEN : 20|1@1+ (1,0) [0|1] "Bool" Vector__XXX
 SG_ SENSE_LINE_65_OPEN : 21|1@1+ (1,0) [0|1] "Bool" Vector__XXX
 SG_ SENSE_LINE_66_OPEN : 22|1@1+ (1,0) [0|1] "Bool" Vector__XXX
 SG_ SENSE_LINE_67_OPEN : 23|1@1+ (1,0) [0|1] "Bool" Vector__XXX
 SG_ SENSE_LINE_68_OPEN : 24|1@1+ (1,0) [0|1] "Bool" Vector__XXX
 SG_ SENSE_LINE_69_OPEN : 25|1@1+ (1,0) [0|1] "Bool" Vector__XXX
 SG_ SENSE_LINE_70_OPEN : 26|1@1+ (1,0) [0|1] "Bool" Vector__XXX
 SG_ SENSE_LINE_71_OPEN : 27|1@1+ (1,0) [0|1] "Bool" Vector__XXX
 SG_ SENSE_LINE_72_LO_OPEN : 28|1@1+ (1,0) [0|1] "Bool" Vector__XXX
 SG_ SENSE_LINE_72_HI_OPEN : 32|1@1+ (1,0) [0|1] "Bool" Vector__XXX
 SG_ SENSE_LINE_73_OPEN : 33|1@1+ (1,0) [0|1] "Bool" Vector__XXX
 SG_ SENSE_LINE_74_OPEN : 34|1@1+ (1,0) [0|1] "Bool" Vector__XXX
 SG_ SENSE_LINE_75_OPEN : 35|1@1+ (1,0) [0|1] "Bool" Vector__XXX
 SG_ SENSE_LINE_76_OPEN : 36|1@1+ (1,0) [0|1] "Bool" Vector__XXX
 SG_ SENSE_LINE_77_OPEN : 37|1@1+ (1,0) [0|1] "Bool" Vector__XXX
 SG_ SENSE_LINE_78_OPEN : 38|1@1+ (1,0) [0|1] "Bool" Vector__XXX
 SG_ SENSE_LINE_79_OPEN : 39|1@1+ (1,0) [0|1] "Bool" Vector__XXX
 SG_ SENSE_LINE_80_OPEN : 40|1@1+ (1,0) [0|1] "Bool" Vector__XXX
 SG_ SENSE_LINE_81_OPEN : 41|1@1+ (1,0) [0|1] "Bool" Vector__XXX
 SG_ SENSE_LINE_82_OPEN : 42|1@1+ (1,0) [0|1] "Bool" Vector__XXX
 SG_ SENSE_LINE_83_OPEN : 43|1@1+ (1,0) [0|1] "Bool" Vector__XXX
 SG_ SENSE_LINE_84_LO_OPEN : 44|1@1+ (1,0) [0|1] "Bool" Vector__XXX
 SG_ SENSE_LINE_84_HI_OPEN : 48|1@1+ (1,0) [0|1] "Bool" Vector__XXX
 SG_ SENSE_LINE_85_OPEN : 49|1@1+ (1,0) [0|1] "Bool" Vector__XXX
 SG_ SENSE_LINE_86_OPEN : 50|1@1+ (1,0) [0|1] "Bool" Vector__XXX
 SG_ SENSE_LINE_87_OPEN : 51|1@1+ (1,0) [0|1] "Bool" Vector__XXX
 SG_ SENSE_LINE_88_OPEN : 52|1@1+ (1,0) [0|1] "Bool" Vector__XXX
 SG_ SENSE_LINE_89_OPEN : 53|1@1+ (1,0) [0|1] "Bool" Vector__XXX
 SG_ SENSE_LINE_90_OPEN : 54|1@1+ (1,0) [0|1] "Bool" Vector__XXX
 SG_ SENSE_LINE_91_OPEN : 55|1@1+ (1,0) [0|1] "Bool" Vector__XXX
 SG_ SENSE_LINE_92_OPEN : 56|1@1+ (1,0) [0|1] "Bool" Vector__XXX
 SG_ SENSE_LINE_93_OPEN : 57|1@1+ (1,0) [0|1] "Bool" Vector__XXX
 SG_ SENSE_LINE_94_OPEN : 58|1@1+ (1,0) [0|1] "Bool" Vector__XXX
 SG_ SENSE_LINE_95_OPEN : 59|1@1+ (1,0) [0|1] "Bool" Vector__XXX
 SG_ SENSE_LINE_96_LO_OPEN : 60|1@1+ (1,0) [0|1] "Bool" Vector__XXX

BO_ 1830 BMS_SENSE_LINE_STATUSES_96_144: 8 BMS
 SG_ SENSE_LINE_96_HI_OPEN : 0|1@1+ (1,0) [0|1] "Bool" Vector__XXX
 SG_ SENSE_LINE_97_OPEN : 1|1@1+ (1,0) [0|1] "Bool" Vector__XXX
 SG_ SENSE_LINE_98_OPEN : 2|1@1+ (1,0) [0|1] "Bool" Vector__XXX
 SG_ SENSE_LINE_99_OPEN : 3|1@1+ (1,0) [0|1] "Bool" Vector__XXX
 SG_ SENSE_LINE_100_OPEN : 4|1@1+ (1,0) [0|1] "Bool" Vector__XXX
 SG_ SENSE_LINE_101_OPEN : 5|1@1+ (1,0) [0|1] "Bool" Vector__XXX
 SG_ SENSE_LINE_102_OPEN : 6|1@1+ (1,0) [0|1] "Bool" Vector__XXX
 SG_ SENSE_LINE_103_OPEN : 7|1@1+ (1,0) [0|1] "Bool" Vector__XXX
 SG_ SENSE_LINE_104_OPEN : 8|1@1+ (1,0) [0|1] "Bool" Vector__XXX
 SG_ SENSE_LINE_105_OPEN : 9|1@1+ (1,0) [0|1] "Bool" Vector__XXX
 SG_ SENSE_LINE_106_OPEN : 10|1@1+ (1,0) [0|1] "Bool" Vector__XXX
 SG_ SENSE_LINE_107_OPEN : 11|1@1+ (1,0) [0|1] "Bool" Vector__XXX
 SG_ SENSE_LINE_108_LO_OPEN : 12|1@1+ (1,0) [0|1] "Bool" Vector__XXX
 SG_ SENSE_LINE_108_HI_OPEN : 16|1@1+ (1,0) [0|1] "Bool" Vector__XXX
 SG_ SENSE_LINE_109_OPEN : 17|1@1+ (1,0) [0|1] "Bool" Vector__XXX
 SG_ SENSE_LINE_110_OPEN : 18|1@1+ (1,0) [0|1] "Bool" Vector__XXX
 SG_ SENSE_LINE_111_OPEN : 19|1@1+ (1,0) [0|1] "Bool" Vector__XXX
 SG_ SENSE_LINE_112_OPEN : 20|1@1+ (1,0) [0|1] "Bool" Vector__XXX
 SG_ SENSE_LINE_113_OPEN : 21|1@1+ (1,0) [0|1] "Bool" Vector__XXX
 SG_ SENSE_LINE_114_OPEN : 22|1@1+ (1,0) [0|1] "Bool" Vector__XXX
 SG_ SENSE_LINE_115_OPEN : 23|1@1+ (1,0) [0|1] "Bool" Vector__XXX
 SG_ SENSE_LINE_116_OPEN : 24|1@1+ (1,0) [0|1] "Bool" Vector__XXX
 SG_ SENSE_LINE_117_OPEN : 25|1@1+ (1,0) [0|1] "Bool" Vector__XXX
 SG_ SENSE_LINE_118_OPEN : 26|1@1+ (1,0) [0|1] "Bool" Vector__XXX
 SG_ SENSE_LINE_119_OPEN : 27|1@1+ (1,0) [0|1] "Bool" Vector__XXX
 SG_ SENSE_LINE_120_LO_OPEN : 28|1@1+ (1,0) [0|1] "Bool" Vector__XXX
 SG_ SENSE_LINE_120_HI_OPEN : 32|1@1+ (1,0) [0|1] "Bool" Vector__XXX
 SG_ SENSE_LINE_121_OPEN : 33|1@1+ (1,0) [0|1] "Bool" Vector__XXX
 SG_ SENSE_LINE_122_OPEN : 34|1@1+ (1,0) [0|1] "Bool" Vector__XXX
 SG_ SENSE_LINE_123_OPEN : 35|1@1+ (1,0) [0|1] "Bool" Vector__XXX
 SG_ SENSE_LINE_124_OPEN : 36|1@1+ (1,0) [0|1] "Bool" Vector__XXX
 SG_ SENSE_LINE_125_OPEN : 37|1@1+ (1,0) [0|1] "Bool" Vector__XXX
 SG_ SENSE_LINE_126_OPEN : 38|1@1+ (1,0) [0|1] "Bool" Vector__XXX
 SG_ SENSE_LINE_127_OPEN : 39|1@1+ (1,0) [0|1] "Bool" Vector__XXX
 SG_ SENSE_LINE_128_OPEN : 40|1@1+ (1,0) [0|1] "Bool" Vector__XXX
 SG_ SENSE_LINE_129_OPEN : 41|1@1+ (1,0) [0|1] "Bool" Vector__XXX
 SG_ SENSE_LINE_130_OPEN : 42|1@1+ (1,0) [0|1] "Bool" Vector__XXX
 SG_ SENSE_LINE_131_OPEN : 43|1@1+ (1,0) [0|1] "Bool" Vector__XXX
 SG_ SENSE_LINE_132_LO_OPEN : 44|1@1+ (1,0) [0|1] "Bool" Vector__XXX
 SG_ SENSE_LINE_132_HI_OPEN : 48|1@1+ (1,0) [0|1] "Bool" Vector__XXX
 SG_ SENSE_LINE_133_OPEN : 49|1@1+ (1,0) [0|1] "Bool" Vector__XXX
 SG_ SENSE_LINE_134_OPEN : 50|1@1+ (1,0) [0|1] "Bool" Vector__XXX
 SG_ SENSE_LINE_135_OPEN : 51|1@1+ (1,0) [0|1] "Bool" Vector__XXX
 SG_ SENSE_LINE_136_OPEN : 52|1@1+ (1,0) [0|1] "Bool" Vector__XXX
 SG_ SENSE_LINE_137_OPEN : 53|1@1+ (1,0) [0|1] "Bool" Vector__XXX
 SG_ SENSE_LINE_138_OPEN : 54|1@1+ (1,0) [0|1] "Bool" Vector__XXX
 SG_ SENSE_LINE_139_OPEN : 55|1@1+ (1,0) [0|1] "Bool" Vector__XXX
 SG_ SENSE_LINE_140_OPEN : 56|1@1+ (1,0) [0|1] "Bool" Vector__XXX
 SG_ SENSE_LINE_141_OPEN : 57|1@1+ (1,0) [0|1] "Bool" Vector__XXX
 SG_ SENSE_LINE_142_OPEN : 58|1@1+ (1,0) [0|1] "Bool" Vector__XXX
 SG_ SENSE_LINE_143_OPEN : 59|1@1+ (1,0) [0|1] "Bool" Vector__XXX
 SG_ SENSE_LINE_144_LO_OPEN : 60|1@1+ (1,0) [0|1] "Bool" Vector__XXX

BO_ 1833 BMS_CELL_BALANCINGS_0_47: 8 BMS
 SG_ CELL_BALANCING_0 : 0|1@1+ (1,0) [0|1] "Bool" Vector__XXX
 SG_ CELL_BALANCING_1 : 1|1@1+ (1,0) [0|1] "Bool" Vector__XXX
 SG_ CELL_BALANCING_2 : 2|1@1+ (1,0) [0|1] "Bool" Vector__XXX
 SG_ CELL_BALANCING_3 : 3|1@1+ (1,0) [0|1] "Bool" Vector__XXX
 SG_ CELL_BALANCING_4 : 4|1@1+ (1,0) [0|1] "Bool" Vector__XXX
 SG_ CELL_BALANCING_5 : 5|1@1+ (1,0) [0|1] "Bool" Vector__XXX
 SG_ CELL_BALANCING_6 : 6|1@1+ (1,0) [0|1] "Bool" Vector__XXX
 SG_ CELL_BALANCING_7 : 7|1@1+ (1,0) [0|1] "Bool" Vector__XXX
 SG_ CELL_BALANCING_8 : 8|1@1+ (1,0) [0|1] "Bool" Vector__XXX
 SG_ CELL_BALANCING_9 : 9|1@1+ (1,0) [0|1] "Bool" Vector__XXX
 SG_ CELL_BALANCING_10 : 10|1@1+ (1,0) [0|1] "Bool" Vector__XXX
 SG_ CELL_BALANCING_11 : 11|1@1+ (1,0) [0|1] "Bool" Vector__XXX
 SG_ CELL_BALANCING_12 : 16|1@1+ (1,0) [0|1] "Bool" Vector__XXX
 SG_ CELL_BALANCING_13 : 17|1@1+ (1,0) [0|1] "Bool" Vector__XXX
 SG_ CELL_BALANCING_14 : 18|1@1+ (1,0) [0|1] "Bool" Vector__XXX
 SG_ CELL_BALANCING_15 : 19|1@1+ (1,0) [0|1] "Bool" Vector__XXX
 SG_ CELL_BALANCING_16 : 20|1@1+ (1,0) [0|1] "Bool" Vector__XXX
 SG_ CELL_BALANCING_17 : 21|1@1+ (1,0) [0|1] "Bool" Vector__XXX
 SG_ CELL_BALANCING_18 : 22|1@1+ (1,0) [0|1] "Bool" Vector__XXX
 SG_ CELL_BALANCING_19 : 23|1@1+ (1,0) [0|1] "Bool" Vector__XXX
 SG_ CELL_BALANCING_20 : 24|1@1+ (1,0) [0|1] "Bool" Vector__XXX
 SG_ CELL_BALANCING_21 : 25|1@1+ (1,0) [0|1] "Bool" Vector__XXX
 SG_ CELL_BALANCING_22 : 26|1@1+ (1,0) [0|1] "Bool" Vector__XXX
 SG_ CELL_BALANCING_23 : 27|1@1+ (1,0) [0|1] "Bool" Vector__XXX
 SG_ CELL_BALANCING_24 : 32|1@1+ (1,0) [0|1] "Bool" Vector__XXX
 SG_ CELL_BALANCING_25 : 33|1@1+ (1,0) [0|1] "Bool" Vector__XXX
 SG_ CELL_BALANCING_26 : 34|1@1+ (1,0) [0|1] "Bool" Vector__XXX
 SG_ CELL_BALANCING_27 : 35|1@1+ (1,0) [0|1] "Bool" Vector__XXX
 SG_ CELL_BALANCING_28 : 36|1@1+ (1,0) [0|1] "Bool" Vector__XXX
 SG_ CELL_BALANCING_29 : 37|1@1+ (1,0) [0|1] "Bool" Vector__XXX
 SG_ CELL_BALANCING_39 : 38|1@1+ (1,0) [0|1] "Bool" Vector__XXX
 SG_ CELL_BALANCING_31 : 39|1@1+ (1,0) [0|1] "Bool" Vector__XXX
 SG_ CELL_BALANCING_32 : 40|1@1+ (1,0) [0|1] "Bool" Vector__XXX
 SG_ CELL_BALANCING_33 : 41|1@1+ (1,0) [0|1] "Bool" Vector__XXX
 SG_ CELL_BALANCING_34 : 42|1@1+ (1,0) [0|1] "Bool" Vector__XXX
 SG_ CELL_BALANCING_35 : 43|1@1+ (1,0) [0|1] "Bool" Vector__XXX
 SG_ CELL_BALANCING_36 : 48|1@1+ (1,0) [0|1] "Bool" Vector__XXX
 SG_ CELL_BALANCING_37 : 49|1@1+ (1,0) [0|1] "Bool" Vector__XXX
 SG_ CELL_BALANCING_38 : 50|1@1+ (1,0) [0|1] "Bool" Vector__XXX
 SG_ CELL_BALANCING_30 : 51|1@1+ (1,0) [0|1] "Bool" Vector__XXX
 SG_ CELL_BALANCING_40 : 52|1@1+ (1,0) [0|1] "Bool" Vector__XXX
 SG_ CELL_BALANCING_41 : 53|1@1+ (1,0) [0|1] "Bool" Vector__XXX
 SG_ CELL_BALANCING_42 : 54|1@1+ (1,0) [0|1] "Bool" Vector__XXX
 SG_ CELL_BALANCING_43 : 55|1@1+ (1,0) [0|1] "Bool" Vector__XXX
 SG_ CELL_BALANCING_44 : 56|1@1+ (1,0) [0|1] "Bool" Vector__XXX
 SG_ CELL_BALANCING_45 : 57|1@1+ (1,0) [0|1] "Bool" Vector__XXX
 SG_ CELL_BALANCING_46 : 58|1@1+ (1,0) [0|1] "Bool" Vector__XXX
 SG_ CELL_BALANCING_47 : 59|1@1+ (1,0) [0|1] "Bool" Vector__XXX

BO_ 1834 BMS_CELL_BALANCINGS_48_95: 8 BMS
 SG_ CELL_BALANCING_48 : 0|1@1+ (1,0) [0|1] "Bool" Vector__XXX
 SG_ CELL_BALANCING_49 : 1|1@1+ (1,0) [0|1] "Bool" Vector__XXX
 SG_ CELL_BALANCING_50 : 2|1@1+ (1,0) [0|1] "Bool" Vector__XXX
 SG_ CELL_BALANCING_51 : 3|1@1+ (1,0) [0|1] "Bool" Vector__XXX
 SG_ CELL_BALANCING_52 : 4|1@1+ (1,0) [0|1] "Bool" Vector__XXX
 SG_ CELL_BALANCING_53 : 5|1@1+ (1,0) [0|1] "Bool" Vector__XXX
 SG_ CELL_BALANCING_54 : 6|1@1+ (1,0) [0|1] "Bool" Vector__XXX
 SG_ CELL_BALANCING_55 : 7|1@1+ (1,0) [0|1] "Bool" Vector__XXX
 SG_ CELL_BALANCING_56 : 8|1@1+ (1,0) [0|1] "Bool" Vector__XXX
 SG_ CELL_BALANCING_57 : 9|1@1+ (1,0) [0|1] "Bool" Vector__XXX
 SG_ CELL_BALANCING_58 : 10|1@1+ (1,0) [0|1] "Bool" Vector__XXX
 SG_ CELL_BALANCING_59 : 11|1@1+ (1,0) [0|1] "Bool" Vector__XXX
 SG_ CELL_BALANCING_60 : 16|1@1+ (1,0) [0|1] "Bool" Vector__XXX
 SG_ CELL_BALANCING_61 : 17|1@1+ (1,0) [0|1] "Bool" Vector__XXX
 SG_ CELL_BALANCING_62 : 18|1@1+ (1,0) [0|1] "Bool" Vector__XXX
 SG_ CELL_BALANCING_63 : 19|1@1+ (1,0) [0|1] "Bool" Vector__XXX
 SG_ CELL_BALANCING_64 : 20|1@1+ (1,0) [0|1] "Bool" Vector__XXX
 SG_ CELL_BALANCING_65 : 21|1@1+ (1,0) [0|1] "Bool" Vector__XXX
 SG_ CELL_BALANCING_66 : 22|1@1+ (1,0) [0|1] "Bool" Vector__XXX
 SG_ CELL_BALANCING_67 : 23|1@1+ (1,0) [0|1] "Bool" Vector__XXX
 SG_ CELL_BALANCING_68 : 24|1@1+ (1,0) [0|1] "Bool" Vector__XXX
 SG_ CELL_BALANCING_69 : 25|1@1+ (1,0) [0|1] "Bool" Vector__XXX
 SG_ CELL_BALANCING_70 : 26|1@1+ (1,0) [0|1] "Bool" Vector__XXX
 SG_ CELL_BALANCING_71 : 27|1@1+ (1,0) [0|1] "Bool" Vector__XXX
 SG_ CELL_BALANCING_72 : 32|1@1+ (1,0) [0|1] "Bool" Vector__XXX
 SG_ CELL_BALANCING_73 : 33|1@1+ (1,0) [0|1] "Bool" Vector__XXX
 SG_ CELL_BALANCING_74 : 34|1@1+ (1,0) [0|1] "Bool" Vector__XXX
 SG_ CELL_BALANCING_75 : 35|1@1+ (1,0) [0|1] "Bool" Vector__XXX
 SG_ CELL_BALANCING_76 : 36|1@1+ (1,0) [0|1] "Bool" Vector__XXX
 SG_ CELL_BALANCING_77 : 37|1@1+ (1,0) [0|1] "Bool" Vector__XXX
 SG_ CELL_BALANCING_78 : 38|1@1+ (1,0) [0|1] "Bool" Vector__XXX
 SG_ CELL_BALANCING_79 : 39|1@1+ (1,0) [0|1] "Bool" Vector__XXX
 SG_ CELL_BALANCING_80 : 40|1@1+ (1,0) [0|1] "Bool" Vector__XXX
 SG_ CELL_BALANCING_81 : 41|1@1+ (1,0) [0|1] "Bool" Vector__XXX
 SG_ CELL_BALANCING_82 : 42|1@1+ (1,0) [0|1] "Bool" Vector__XXX
 SG_ CELL_BALANCING_83 : 43|1@1+ (1,0) [0|1] "Bool" Vector__XXX
 SG_ CELL_BALANCING_84 : 48|1@1+ (1,0) [0|1] "Bool" Vector__XXX
 SG_ CELL_BALANCING_85 : 49|1@1+ (1,0) [0|1] "Bool" Vector__XXX
 SG_ CELL_BALANCING_86 : 50|1@1+ (1,0) [0|1] "Bool" Vector__XXX
 SG_ CELL_BALANCING_87 : 51|1@1+ (1,0) [0|1] "Bool" Vector__XXX
 SG_ CELL_BALANCING_88 : 52|1@1+ (1,0) [0|1] "Bool" Vector__XXX
 SG_ CELL_BALANCING_89 : 53|1@1+ (1,0) [0|1] "Bool" Vector__XXX
 SG_ CELL_BALANCING_90 : 54|1@1+ (1,0) [0|1] "Bool" Vector__XXX
 SG_ CELL_BALANCING_91 : 55|1@1+ (1,0) [0|1] "Bool" Vector__XXX
 SG_ CELL_BALANCING_92 : 56|1@1+ (1,0) [0|1] "Bool" Vector__XXX
 SG_ CELL_BALANCING_93 : 57|1@1+ (1,0) [0|1] "Bool" Vector__XXX
 SG_ CELL_BALANCING_94 : 58|1@1+ (1,0) [0|1] "Bool" Vector__XXX
 SG_ CELL_BALANCING_95 : 59|1@1+ (1,0) [0|1] "Bool" Vector__XXX

BO_ 1835 BMS_CELL_BALANCINGS_96_143: 8 BMS
 SG_ CELL_BALANCING_96 : 0|1@1+ (1,0) [0|1] "Bool" Vector__XXX
 SG_ CELL_BALANCING_97 : 1|1@1+ (1,0) [0|1] "Bool" Vector__XXX
 SG_ CELL_BALANCING_98 : 2|1@1+ (1,0) [0|1] "Bool" Vector__XXX
 SG_ CELL_BALANCING_99 : 3|1@1+ (1,0) [0|1] "Bool" Vector__XXX
 SG_ CELL_BALANCING_100 : 4|1@1+ (1,0) [0|1] "Bool" Vector__XXX
 SG_ CELL_BALANCING_101 : 5|1@1+ (1,0) [0|1] "Bool" Vector__XXX
 SG_ CELL_BALANCING_102 : 6|1@1+ (1,0) [0|1] "Bool" Vector__XXX
 SG_ CELL_BALANCING_103 : 7|1@1+ (1,0) [0|1] "Bool" Vector__XXX
 SG_ CELL_BALANCING_104 : 8|1@1+ (1,0) [0|1] "Bool" Vector__XXX
 SG_ CELL_BALANCING_105 : 9|1@1+ (1,0) [0|1] "Bool" Vector__XXX
 SG_ CELL_BALANCING_106 : 10|1@1+ (1,0) [0|1] "Bool" Vector__XXX
 SG_ CELL_BALANCING_107 : 11|1@1+ (1,0) [0|1] "Bool" Vector__XXX
 SG_ CELL_BALANCING_108 : 16|1@1+ (1,0) [0|1] "Bool" Vector__XXX
 SG_ CELL_BALANCING_109 : 17|1@1+ (1,0) [0|1] "Bool" Vector__XXX
 SG_ CELL_BALANCING_110 : 18|1@1+ (1,0) [0|1] "Bool" Vector__XXX
 SG_ CELL_BALANCING_111 : 19|1@1+ (1,0) [0|1] "Bool" Vector__XXX
 SG_ CELL_BALANCING_112 : 20|1@1+ (1,0) [0|1] "Bool" Vector__XXX
 SG_ CELL_BALANCING_113 : 21|1@1+ (1,0) [0|1] "Bool" Vector__XXX
 SG_ CELL_BALANCING_114 : 22|1@1+ (1,0) [0|1] "Bool" Vector__XXX
 SG_ CELL_BALANCING_115 : 23|1@1+ (1,0) [0|1] "Bool" Vector__XXX
 SG_ CELL_BALANCING_116 : 24|1@1+ (1,0) [0|1] "Bool" Vector__XXX
 SG_ CELL_BALANCING_117 : 25|1@1+ (1,0) [0|1] "Bool" Vector__XXX
 SG_ CELL_BALANCING_118 : 26|1@1+ (1,0) [0|1] "Bool" Vector__XXX
 SG_ CELL_BALANCING_119 : 27|1@1+ (1,0) [0|1] "Bool" Vector__XXX
 SG_ CELL_BALANCING_120 : 32|1@1+ (1,0) [0|1] "Bool" Vector__XXX
 SG_ CELL_BALANCING_121 : 33|1@1+ (1,0) [0|1] "Bool" Vector__XXX
 SG_ CELL_BALANCING_122 : 34|1@1+ (1,0) [0|1] "Bool" Vector__XXX
 SG_ CELL_BALANCING_123 : 35|1@1+ (1,0) [0|1] "Bool" Vector__XXX
 SG_ CELL_BALANCING_124 : 36|1@1+ (1,0) [0|1] "Bool" Vector__XXX
 SG_ CELL_BALANCING_125 : 37|1@1+ (1,0) [0|1] "Bool" Vector__XXX
 SG_ CELL_BALANCING_126 : 38|1@1+ (1,0) [0|1] "Bool" Vector__XXX
 SG_ CELL_BALANCING_127 : 39|1@1+ (1,0) [0|1] "Bool" Vector__XXX
 SG_ CELL_BALANCING_128 : 40|1@1+ (1,0) [0|1] "Bool" Vector__XXX
 SG_ CELL_BALANCING_129 : 41|1@1+ (1,0) [0|1] "Bool" Vector__XXX
 SG_ CELL_BALANCING_130 : 42|1@1+ (1,0) [0|1] "Bool" Vector__XXX
 SG_ CELL_BALANCING_131 : 43|1@1+ (1,0) [0|1] "Bool" Vector__XXX
 SG_ CELL_BALANCING_132 : 48|1@1+ (1,0) [0|1] "Bool" Vector__XXX
 SG_ CELL_BALANCING_133 : 49|1@1+ (1,0) [0|1] "Bool" Vector__XXX
 SG_ CELL_BALANCING_134 : 50|1@1+ (1,0) [0|1] "Bool" Vector__XXX
 SG_ CELL_BALANCING_135 : 51|1@1+ (1,0) [0|1] "Bool" Vector__XXX
 SG_ CELL_BALANCING_136 : 52|1@1+ (1,0) [0|1] "Bool" Vector__XXX
 SG_ CELL_BALANCING_137 : 53|1@1+ (1,0) [0|1] "Bool" Vector__XXX
 SG_ CELL_BALANCING_138 : 54|1@1+ (1,0) [0|1] "Bool" Vector__XXX
 SG_ CELL_BALANCING_139 : 55|1@1+ (1,0) [0|1] "Bool" Vector__XXX
 SG_ CELL_BALANCING_140 : 56|1@1+ (1,0) [0|1] "Bool" Vector__XXX
 SG_ CELL_BALANCING_141 : 57|1@1+ (1,0) [0|1] "Bool" Vector__XXX
 SG_ CELL_BALANCING_142 : 58|1@1+ (1,0) [0|1] "Bool" Vector__XXX
 SG_ CELL_BALANCING_143 : 59|1@1+ (1,0) [0|1] "Bool" Vector__XXX

BO_ 1876 BMS_LTC_TEMPERATURES_0_5: 8 BMS
 SG_ BMS_LTC_0_TEMPERATURE : 0|10@1+ (0.125,-28) [-28|100] "C" Vector__XXX
 SG_ BMS_LTC_1_TEMPERATURE : 10|10@1+ (0.125,-28) [-28|100] "C" Vector__XXX
 SG_ BMS_LTC_2_TEMPERATURE : 20|10@1+ (0.125,-28) [-28|100] "C" Vector__XXX
 SG_ BMS_LTC_3_TEMPERATURE : 30|10@1+ (0.125,-28) [-28|100] "C" Vector__XXX
 SG_ BMS_LTC_4_TEMPERATURE : 40|10@1+ (0.125,-28) [-28|100] "C" Vector__XXX
 SG_ BMS_LTC_5_TEMPERATURE : 50|10@1+ (0.125,-28) [-28|100] "C" Vector__XXX

BO_ 1877 BMS_LTC_TEMPERATURES_6_11: 8 BMS
 SG_ BMS_LTC_6_TEMPERATURE : 0|10@1+ (0.125,-28) [-28|100] "C" Vector__XXX
 SG_ BMS_LTC_7_TEMPERATURE : 10|10@1+ (0.125,-28) [-28|100] "C" Vector__XXX
 SG_ BMS_LTC_8_TEMPERATURE : 20|10@1+ (0.125,-28) [-28|100] "C" Vector__XXX
 SG_ BMS_LTC_9_TEMPERATURE : 30|10@1+ (0.125,-28) [-28|100] "C" Vector__XXX
 SG_ BMS_LTC_10_TEMPERATURE : 40|10@1+ (0.125,-28) [-28|100] "C" Vector__XXX
 SG_ BMS_LTC_11_TEMPERATURE : 50|10@1+ (0.125,-28) [-28|100] "C" Vector__XXX

BO_ 1872 VCU_EEPROM_COMMAND: 6 Vector__XXX
 SG_ VCU_EEPROM_COMMAND_DATA_ADDRESS : 0|16@1+ (1,0) [0|1] "" Vector__XXX
 SG_ VCU_EEPROM_COMMAND_DATA : 16|32@1+ (1,0) [0|1] "" Vector__XXX

BO_ 1873 VCU_EEPROM_RESPONSE: 6 Vector__XXX
 SG_ VCU_EEPROM_RESPONSE_DATA_ADDRESS : 0|16@1+ (1,0) [0|1] "" Vector__XXX
 SG_ VCU_EEPROM_RESPONSE_DATA : 16|32@1+ (1,0) [0|1] "" Vector__XXX

BO_ 1874 BMS_EEPROM_COMMAND: 6 Vector__XXX
 SG_ BMS_EEPROM_COMMAND_DATA_ADDRESS : 0|16@1+ (1,0) [0|1] "" Vector__XXX
 SG_ BMS_EEPROM_COMMAND_DATA : 16|32@1+ (1,0) [0|1] "" Vector__XXX

BO_ 1875 BMS_EEPROM_RESPONSE: 6 Vector__XXX
 SG_ BMS_EEPROM_RESPONSE_DATA_ADDRESS : 0|16@1+ (1,0) [0|1] "" Vector__XXX
 SG_ BMS_EEPROM_RESPONSE_DATA : 16|32@1+ (1,0) [0|1] "" Vector__XXX

CM_ SG_ 1280 RL_TEMPERATURE_EXTERNAL "TODO(Barach): No documented scale factor";
CM_ SG_ 1280 RL_TEMPERATURE_SENSOR_MOTOR "TODO(Barach): No documented scale factor";
CM_ SG_ 1956 THETA_TARGET "Returns the calculated angular position of your servo, [-180, 180 - SF]";
CM_ SG_ 1956 WING_STATUS "Returns the Wing Status, DRS_OPEN_STEADY=>0, DRS_OPEN_TRANSITION=>1, DRS_CLOSED_STEADY=>2, DRS_CLOSED_TRANSITION=>3, DRS_STALL=>4";
CM_ SG_ 1956 EEPROM_STATUS "Returns EEPROM_STATUS, FAILED=>0, INVALID=>1, READY=>3";
CM_ SG_ 1956 STALLED "Returns a boolean representing the stall condition, 0=>NOT stall, 1=>STALL";

BA_DEF_  "BusType" STRING ;
BA_DEF_DEF_  "BusType" "CAN";
